VERSION "HSCAN6"

NS_ :

BS_:

BU_: BMS Tester TBOX VCU ISC SAC TC WLC

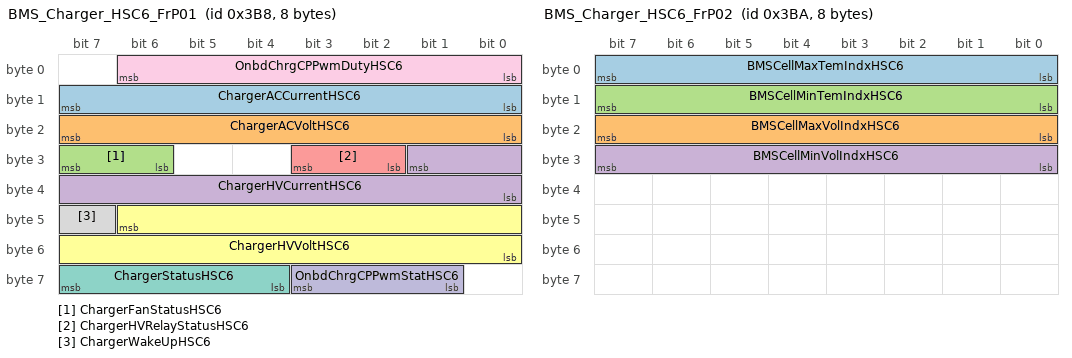
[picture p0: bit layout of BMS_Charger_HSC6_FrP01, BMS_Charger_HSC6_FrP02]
BO_ 952 BMS_Charger_HSC6_FrP01: 8 BMS
 SG_ ChargerACCurrentHSC6 : 15|8@0- (0.2,0) [0|50.8] "A"  Tester
 SG_ ChargerACVoltHSC6 : 23|8@0- (2,0) [0|508] "V"  Tester
 SG_ ChargerFanStatusHSC6 : 31|2@0+ (1,0) [0|3] ""  Tester
 SG_ ChargerHVCurrentHSC6 : 25|10@0- (0.05,0) [0|51.1] "A"  Tester,TBOX
 SG_ ChargerHVRelayStatusHSC6 : 27|2@0+ (1,0) [0|3] ""  Tester
 SG_ ChargerHVVoltHSC6 : 46|15@0- (0.02,0) [0|655.32] "V"  Tester,TBOX
 SG_ ChargerStatusHSC6 : 63|4@0+ (1,0) [0|15] ""  Tester,TBOX
 SG_ ChargerWakeUpHSC6 : 47|1@0+ (1,0) [0|1] ""  Tester
 SG_ OnbdChrgCPPwmDutyHSC6 : 6|7@0+ (1,0) [0|127] ""  Tester
 SG_ OnbdChrgCPPwmStatHSC6 : 59|3@0+ (1,0) [0|7] ""  TBOX

BO_ 954 BMS_Charger_HSC6_FrP02: 8 BMS
 SG_ BMSCellMaxTemIndxHSC6 : 7|8@0+ (1,0) [0|254] ""  TBOX
 SG_ BMSCellMaxVolIndxHSC6 : 23|8@0+ (1,0) [0|254] ""  TBOX
 SG_ BMSCellMinTemIndxHSC6 : 15|8@0+ (1,0) [0|254] ""  TBOX
 SG_ BMSCellMinVolIndxHSC6 : 31|8@0+ (1,0) [0|254] ""  TBOX

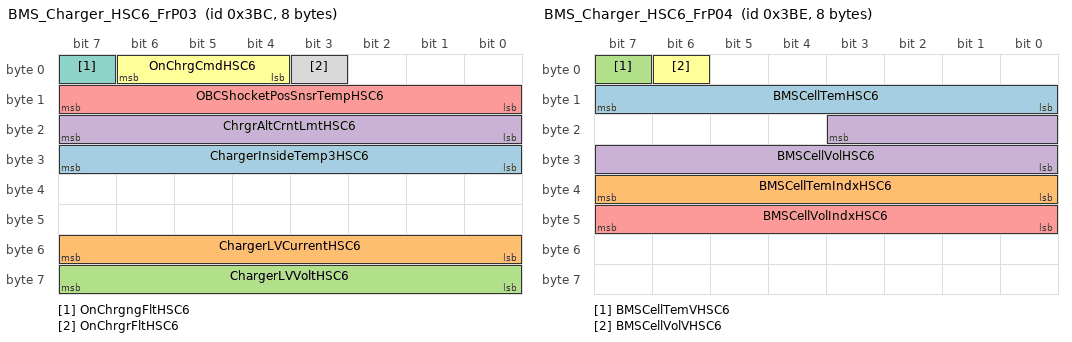
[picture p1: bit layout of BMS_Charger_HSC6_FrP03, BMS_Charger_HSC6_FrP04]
BO_ 956 BMS_Charger_HSC6_FrP03: 8 BMS
 SG_ ChargerInsideTemp3HSC6 : 31|8@0+ (1,-40) [-40|214] "DegC"  TBOX
 SG_ ChargerLVCurrentHSC6 : 55|8@0- (0.1,0) [0|25.4] "A"  Tester
 SG_ ChargerLVVoltHSC6 : 63|8@0- (0.1,0) [0|25.4] "V"  Tester
 SG_ ChrgrAltCrntLmtHSC6 : 23|8@0- (0.5,0) [0|127] "A"  Tester
 SG_ OBCShocketPosSnsrTempHSC6 : 15|8@0+ (1,-40) [-40|214] "¡æ"  TBOX
 SG_ OnChrgCmdHSC6 : 6|3@0+ (1,0) [0|7] ""  Tester
 SG_ OnChrgngFltHSC6 : 7|1@0+ (1,0) [0|1] ""  Tester
 SG_ OnChrgrFltHSC6 : 3|1@0+ (1,0) [0|1] ""  Tester

BO_ 958 BMS_Charger_HSC6_FrP04: 8 BMS
 SG_ BMSCellTemHSC6 : 15|8@0+ (1,-40) [-40|215] "E=N*1-40"  TBOX
 SG_ BMSCellTemIndxHSC6 : 39|8@0+ (1,0) [0|254] "E=N*1"  TBOX
 SG_ BMSCellTemVHSC6 : 7|1@0+ (1,0) [0|1] ""  TBOX
 SG_ BMSCellVolHSC6 : 19|12@0+ (0.001,1) [1|5.095] "E=N*0.001+1 V"  TBOX
 SG_ BMSCellVolIndxHSC6 : 47|8@0+ (1,0) [0|254] "E=N*1"  TBOX
 SG_ BMSCellVolVHSC6 : 6|1@0+ (1,0) [0|1] ""  TBOX

BO_ 659 BMS_HSC6_FrP00: 8 BMS
 SG_ BMSBalancingDoneHSC6 : 18|1@0+ (1,0) [0|1] ""  Tester
 SG_ BMSBalancingStatusHSC6 : 24|1@0+ (1,0) [0|1] ""  Tester,TBOX
 SG_ BMSCellBalancingCountHSC6 : 15|8@0+ (1,0) [0|253] ""  Tester
 SG_ BMSCellOverVoltHSC6 : 39|1@0+ (1,0) [0|1] ""  Tester
 SG_ BMSCellUnderVoltHSC6 : 19|1@0+ (1,0) [0|1] ""  Tester
 SG_ BMSContactorPowerCmdHSC6 : 16|1@0+ (1,0) [0|1] ""  Tester
 SG_ BMSContactorPowerMonHSC6 : 25|1@0+ (1,0) [0|1] ""  Tester
 SG_ BMSCrashCircuitStatusHSC6 : 17|1@0+ (1,0) [0|1] ""  Tester
 SG_ BMSEEpromWipHSC6 : 38|1@0+ (1,0) [0|1] ""  Tester
 SG_ BMSLVBatInputHSC6 : 7|8@0+ (0.1,0) [0|25.3] "V"  Tester,TBOX
 SG_ BMSModuleEnableHSC6 : 27|1@0+ (1,0) [0|1] ""  Tester
 SG_ BMSNegRelayStatusHSC6 : 47|2@0+ (1,0) [0|3] ""  Tester,TBOX
 SG_ BMSOffbdChargerWakeupHSC6 : 30|1@0+ (1,0) [0|1] ""  Tester
 SG_ BMSOnbdChargerWakeupHSC6 : 28|1@0+ (1,0) [0|1] ""  Tester
 SG_ BMSPosRelayStatusHSC6 : 33|2@0+ (1,0) [0|3] ""  Tester,TBOX
 SG_ BMSPreRelayStatusHSC6 : 35|2@0+ (1,0) [0|3] ""  Tester,TBOX
 SG_ BMSPTIsolationLevelHSC6 : 37|2@0+ (1,0) [0|3] ""  Tester
 SG_ BMSReadyHSC6 : 26|1@0+ (1,0) [0|1] ""  Tester
 SG_ BMSRelayStepHSC6 : 23|4@0+ (1,0) [0|15] ""  Tester,TBOX
 SG_ BMSVehicleWakeupHSC6 : 29|1@0+ (1,0) [0|1] ""  Tester,TBOX

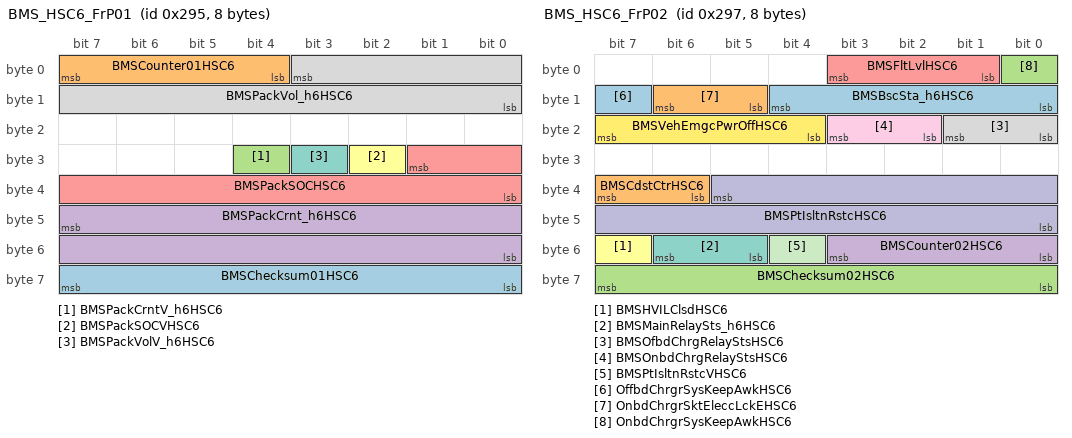
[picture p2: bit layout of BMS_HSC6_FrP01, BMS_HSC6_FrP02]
BO_ 661 BMS_HSC6_FrP01: 8 BMS
 SG_ BMSChecksum01HSC6 : 63|8@0+ (1,0) [0|255] ""  VCU
 SG_ BMSCounter01HSC6 : 7|4@0+ (1,0) [0|15] "count value"  VCU
 SG_ BMSPackCrntV_h6HSC6 : 28|1@0+ (1,0) [0|1] ""  Tester,TBOX,VCU,ISC,SAC,TC
 SG_ BMSPackCrnt_h6HSC6 : 47|16@0+ (0.05,-1000) [-1000|2276.75] "A"  Tester,TBOX,VCU,ISC,SAC,TC
 SG_ BMSPackSOCHSC6 : 25|10@0+ (0.1,0) [0|102.3] "%"  Tester,TBOX,VCU,ISC,SAC,TC
 SG_ BMSPackSOCVHSC6 : 26|1@0+ (1,0) [0|1] ""  Tester,TBOX,VCU,ISC,SAC,TC
 SG_ BMSPackVolV_h6HSC6 : 27|1@0+ (1,0) [0|1] ""  TBOX,VCU,ISC,SAC,TC
 SG_ BMSPackVol_h6HSC6 : 3|12@0+ (0.25,0) [0|1023.75] "V"  TBOX,VCU,ISC,SAC,TC

BO_ 663 BMS_HSC6_FrP02: 8 BMS
 SG_ BMSBscSta_h6HSC6 : 12|5@0+ (1,0) [0|31] ""  TBOX,VCU,ISC,SAC,TC
 SG_ BMSCdstCtrHSC6 : 39|2@0+ (1,0) [0|3] ""  TBOX,VCU
 SG_ BMSChecksum02HSC6 : 63|8@0+ (1,0) [0|255] ""  VCU
 SG_ BMSCounter02HSC6 : 51|4@0+ (1,0) [0|15] "count value"  VCU,ISC,SAC,TC
 SG_ BMSFltLvlHSC6 : 3|3@0+ (1,0) [0|7] ""  TBOX,VCU
 SG_ BMSHVILClsdHSC6 : 55|1@0+ (1,0) [0|1] ""  TBOX,VCU
 SG_ BMSMainRelaySts_h6HSC6 : 54|2@0+ (1,0) [0|3] ""  TBOX,VCU,ISC,SAC,TC
 SG_ BMSOfbdChrgRelayStsHSC6 : 17|2@0+ (1,0) [0|3] ""  Tester
 SG_ BMSOnbdChrgRelayStsHSC6 : 19|2@0+ (1,0) [0|3] ""  Tester
 SG_ BMSPtIsltnRstcHSC6 : 37|14@0+ (0.5,0) [0|8191.5] "kOhm"  TBOX,VCU
 SG_ BMSPtIsltnRstcVHSC6 : 52|1@0+ (1,0) [0|1] ""  TBOX,VCU
 SG_ BMSVehEmgcPwrOffHSC6 : 23|4@0+ (1,0) [0|15] ""  Tester
 SG_ OffbdChrgrSysKeepAwkHSC6 : 15|1@0+ (1,0) [0|1] ""  Tester,TBOX,VCU
 SG_ OnbdChrgrSktEleccLckEHSC6 : 14|2@0+ (1,0) [0|3] ""  VCU
 SG_ OnbdChrgrSysKeepAwkHSC6 : 0|1@0+ (1,0) [0|1] ""  Tester,TBOX,VCU

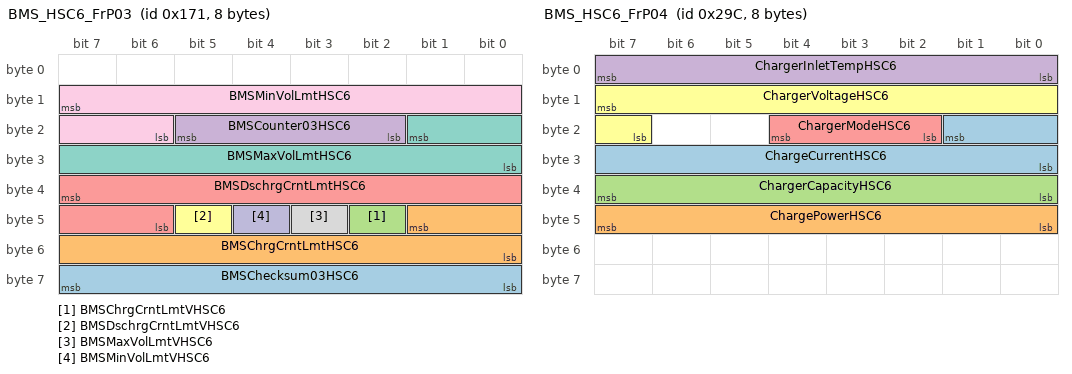
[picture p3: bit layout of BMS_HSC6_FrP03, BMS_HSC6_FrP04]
BO_ 369 BMS_HSC6_FrP03: 8 BMS
 SG_ BMSChecksum03HSC6 : 63|8@0+ (1,0) [0|255] ""  ISC,SAC,TC
 SG_ BMSChrgCrntLmtHSC6 : 41|10@0+ (1,-1023) [-1023|0] "A"  VCU,ISC,SAC,TC
 SG_ BMSChrgCrntLmtVHSC6 : 42|1@0+ (1,0) [0|1] ""  VCU,ISC,SAC,TC
 SG_ BMSCounter03HSC6 : 21|4@0+ (1,0) [0|15] "count value"  ISC,SAC,TC
 SG_ BMSDschrgCrntLmtHSC6 : 39|10@0+ (1,0) [0|1023] "A"  VCU,ISC,SAC,TC
 SG_ BMSDschrgCrntLmtVHSC6 : 45|1@0+ (1,0) [0|1] ""  VCU,ISC,SAC,TC
 SG_ BMSMaxVolLmtHSC6 : 17|10@0+ (1,0) [0|1023] "V"  ISC,SAC,TC
 SG_ BMSMaxVolLmtVHSC6 : 43|1@0+ (1,0) [0|1] ""  ISC,SAC,TC
 SG_ BMSMinVolLmtHSC6 : 15|10@0+ (1,0) [0|1023] "V"  ISC,SAC,TC
 SG_ BMSMinVolLmtVHSC6 : 44|1@0+ (1,0) [0|1] ""  ISC,SAC,TC

BO_ 668 BMS_HSC6_FrP04: 8 BMS
 SG_ ChargeCurrentHSC6 : 17|10@0+ (0.02,0) [0|20.44] "fail"  Tester
 SG_ ChargePowerHSC6 : 47|8@0+ (0.05,0) [0|12.7] "kw"  Tester
 SG_ ChargerCapacityHSC6 : 39|8@0- (1,0) [0|254] "Ah"  Tester
 SG_ ChargerInletTempHSC6 : 7|8@0+ (1,-40) [-40|214] "DegC"  Tester
 SG_ ChargerModeHSC6 : 20|3@0+ (1,0) [0|7] ""  Tester
 SG_ ChargerVoltageHSC6 : 15|9@0+ (1,0) [0|430] ""  Tester

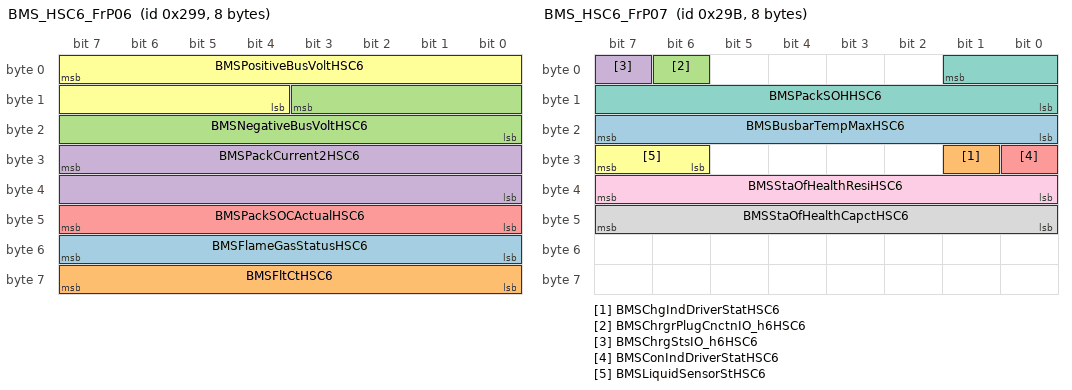
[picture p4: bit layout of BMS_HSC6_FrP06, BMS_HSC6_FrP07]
BO_ 665 BMS_HSC6_FrP06: 8 BMS
 SG_ BMSFlameGasStatusHSC6 : 55|8@0+ (1,0) [0|255] "%"  Tester
 SG_ BMSFltCtHSC6 : 63|8@0+ (1,0) [0|255] ""  Tester
 SG_ BMSNegativeBusVoltHSC6 : 11|12@0+ (0.25,-500) [-500|523.25] "V"  Tester
 SG_ BMSPackCurrent2HSC6 : 31|16@0+ (0.025,-1000) [-1000|638.325] "A"  Tester
 SG_ BMSPackSOCActualHSC6 : 47|8@0+ (0.5,0) [0|126.5] "%"  Tester
 SG_ BMSPositiveBusVoltHSC6 : 7|12@0+ (0.25,0) [0|1023.25] "V"  Tester

BO_ 667 BMS_HSC6_FrP07: 8 BMS
 SG_ BMSBusbarTempMaxHSC6 : 23|8@0+ (0.5,-40) [-40|86.5] "DegC"  Tester
 SG_ BMSChgIndDriverStatHSC6 : 25|1@0+ (1,0) [0|1] ""  Tester
 SG_ BMSChrgrPlugCnctnIO_h6HSC6 : 6|1@0+ (1,0) [0|1] ""  TBOX
 SG_ BMSChrgStsIO_h6HSC6 : 7|1@0+ (1,0) [0|1] ""  TBOX
 SG_ BMSConIndDriverStatHSC6 : 24|1@0+ (1,0) [0|1] ""  Tester
 SG_ BMSLiquidSensorStHSC6 : 31|2@0+ (1,0) [0|3] ""  Tester
 SG_ BMSPackSOHHSC6 : 1|10@0+ (0.1,0) [0|102.1] "%"  Tester,TBOX
 SG_ BMSStaOfHealthCapctHSC6 : 47|8@0+ (0.5,0) [0|126.5] "%"  Tester,TBOX
 SG_ BMSStaOfHealthResiHSC6 : 39|8@0+ (0.5,0) [0|126.5] "%"  Tester,TBOX

BO_ 1100 BMS_HSC6_FrP08: 1 BMS
 SG_ keep_network_BMSHSC6 : 0|1@0+ (1,0) [0|1] ""  TBOX
 SG_ keep_network_BMSHSC6_UB : 1|1@0+ (1,0) [0|1] ""  TBOX

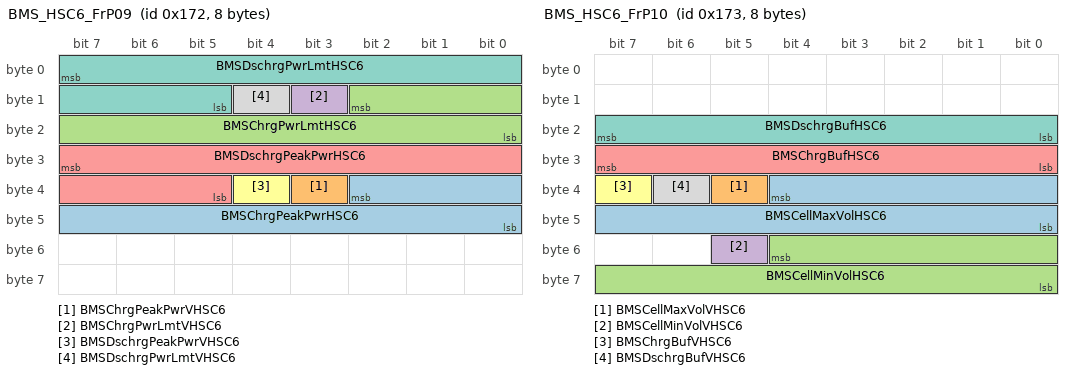
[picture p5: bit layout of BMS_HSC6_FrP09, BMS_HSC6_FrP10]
BO_ 370 BMS_HSC6_FrP09: 8 BMS
 SG_ BMSChrgPeakPwrHSC6 : 34|11@0+ (0.2,0) [0|409.4] "kw"  VCU
 SG_ BMSChrgPeakPwrVHSC6 : 35|1@0+ (1,0) [0|1] ""  VCU
 SG_ BMSChrgPwrLmtHSC6 : 10|11@0+ (0.2,0) [0|409.4] "kw"  VCU
 SG_ BMSChrgPwrLmtVHSC6 : 11|1@0+ (1,0) [0|1] ""  VCU
 SG_ BMSDschrgPeakPwrHSC6 : 31|11@0+ (0.2,0) [0|409.4] "kw"  VCU
 SG_ BMSDschrgPeakPwrVHSC6 : 36|1@0+ (1,0) [0|1] ""  VCU
 SG_ BMSDschrgPwrLmtHSC6 : 7|11@0+ (0.2,0) [0|409.4] "kw"  VCU
 SG_ BMSDschrgPwrLmtVHSC6 : 12|1@0+ (1,0) [0|1] ""  VCU

BO_ 371 BMS_HSC6_FrP10: 8 BMS
 SG_ BMSCellMaxVolHSC6 : 36|13@0+ (0.001,0) [0|8.191] "V"  Tester,TBOX
 SG_ BMSCellMaxVolVHSC6 : 37|1@0+ (1,0) [0|1] ""  Tester,TBOX
 SG_ BMSCellMinVolHSC6 : 52|13@0+ (0.001,0) [0|8.191] "V"  Tester,TBOX
 SG_ BMSCellMinVolVHSC6 : 53|1@0+ (1,0) [0|1] ""  Tester,TBOX
 SG_ BMSChrgBufHSC6 : 31|8@0+ (0.5,0) [0|127.5] "%"  VCU
 SG_ BMSChrgBufVHSC6 : 39|1@0+ (1,0) [0|1] ""  VCU
 SG_ BMSDschrgBufHSC6 : 23|8@0+ (0.5,0) [0|127.5] "%"  VCU
 SG_ BMSDschrgBufVHSC6 : 38|1@0+ (1,0) [0|1] ""  VCU

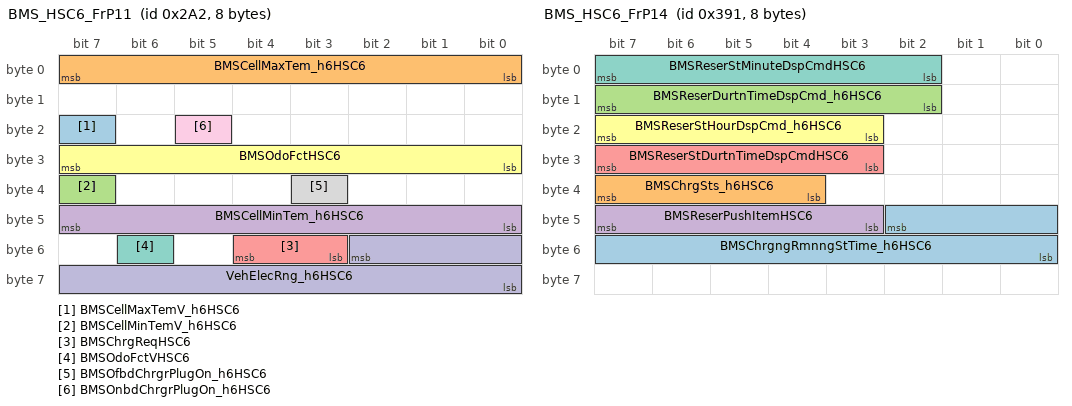
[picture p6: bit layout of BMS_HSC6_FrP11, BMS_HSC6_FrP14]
BO_ 674 BMS_HSC6_FrP11: 8 BMS
 SG_ BMSCellMaxTemV_h6HSC6 : 23|1@0+ (1,0) [0|1] ""  TBOX
 SG_ BMSCellMaxTem_h6HSC6 : 7|8@0+ (0.5,-40) [-40|87.5] "DegC"  TBOX
 SG_ BMSCellMinTemV_h6HSC6 : 39|1@0+ (1,0) [0|1] ""  TBOX
 SG_ BMSCellMinTem_h6HSC6 : 47|8@0+ (0.5,-40) [-40|87.5] "Deg C"  TBOX
 SG_ BMSChrgReqHSC6 : 52|2@0+ (1,0) [0|3] ""  VCU
 SG_ BMSOdoFctHSC6 : 31|8@0+ (0.5,0) [0|127.5] "%"  Tester
 SG_ BMSOdoFctVHSC6 : 54|1@0+ (1,0) [0|1] ""  Tester
 SG_ BMSOfbdChrgrPlugOn_h6HSC6 : 35|1@0+ (1,0) [0|1] ""  VCU
 SG_ BMSOnbdChrgrPlugOn_h6HSC6 : 21|1@0+ (1,0) [0|1] ""  TBOX
 SG_ VehElecRng_h6HSC6 : 50|11@0+ (1,0) [0|2047] "km"  TBOX

BO_ 939 BMS_HSC6_FrP12: 8 BMS
 SG_ HVBatElecEnrgAvgRate_h6HSC6 : 25|10@0+ (0.1,-20) [-20|82.3] "kwh/100km"  TBOX

BO_ 940 BMS_HSC6_FrP13: 8 BMS
 SG_ BMSPackSOCDspV_h6HSC6 : 37|1@0+ (1,0) [0|1] ""  TBOX
 SG_ BMSPackSOCDsp_h6HSC6 : 17|10@0+ (0.1,0) [0|102.3] "%"  TBOX

BO_ 913 BMS_HSC6_FrP14: 8 BMS
 SG_ BMSChrgngRmnngStTime_h6HSC6 : 42|11@0+ (1,0) [0|2047] "minute"  TBOX
 SG_ BMSChrgSts_h6HSC6 : 39|4@0+ (1,0) [0|15] ""  TBOX
 SG_ BMSReserDurtnTimeDspCmd_h6HSC6 : 15|6@0+ (0.5,0) [0|20] ""  TBOX
 SG_ BMSReserPushItemHSC6 : 47|5@0+ (1,0) [0|31] ""  TBOX
 SG_ BMSReserStDurtnTimeDspCmdHSC6 : 31|5@0+ (1,0) [0|23] ""  TBOX
 SG_ BMSReserStHourDspCmd_h6HSC6 : 23|5@0+ (1,0) [0|23] ""  TBOX
 SG_ BMSReserStMinuteDspCmdHSC6 : 7|6@0+ (1,0) [0|59] ""  TBOX

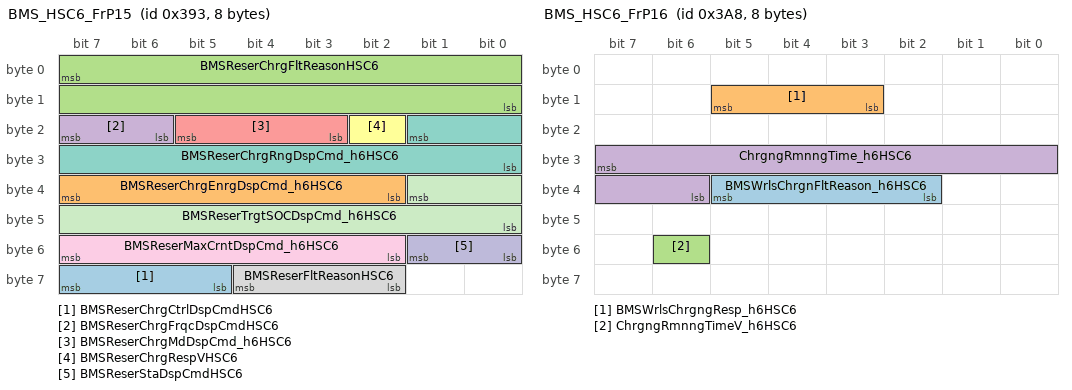
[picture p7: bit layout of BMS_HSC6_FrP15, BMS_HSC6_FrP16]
BO_ 915 BMS_HSC6_FrP15: 8 BMS
 SG_ BMSReserChrgCtrlDspCmdHSC6 : 63|3@0+ (1,0) [0|7] ""  TBOX
 SG_ BMSReserChrgEnrgDspCmd_h6HSC6 : 39|6@0+ (1,0) [0|63] ""  TBOX
 SG_ BMSReserChrgFltReasonHSC6 : 7|16@0+ (1,0) [0|65535] ""  TBOX
 SG_ BMSReserChrgFrqcDspCmdHSC6 : 23|2@0+ (1,0) [0|3] ""  TBOX
 SG_ BMSReserChrgMdDspCmd_h6HSC6 : 21|3@0+ (1,0) [0|7] ""  TBOX
 SG_ BMSReserChrgRespVHSC6 : 18|1@0+ (1,0) [0|1] ""  TBOX
 SG_ BMSReserChrgRngDspCmd_h6HSC6 : 17|10@0+ (1,0) [0|1023] ""  TBOX
 SG_ BMSReserFltReasonHSC6 : 60|3@0+ (1,0) [0|7] ""  TBOX
 SG_ BMSReserMaxCrntDspCmd_h6HSC6 : 55|6@0+ (1,0) [0|32] ""  TBOX
 SG_ BMSReserStaDspCmdHSC6 : 49|2@0+ (1,0) [0|3] ""  TBOX
 SG_ BMSReserTrgtSOCDspCmd_h6HSC6 : 33|10@0+ (0.1,0) [0|102.3] ""  TBOX

BO_ 936 BMS_HSC6_FrP16: 8 BMS
 SG_ BMSWrlsChrgnFltReason_h6HSC6 : 37|4@0+ (1,0) [0|15] ""  TBOX
 SG_ BMSWrlsChrgngResp_h6HSC6 : 13|3@0+ (1,0) [0|7] ""  TBOX
 SG_ ChrgngRmnngTimeV_h6HSC6 : 54|1@0+ (1,0) [0|1] ""  TBOX
 SG_ ChrgngRmnngTime_h6HSC6 : 31|10@0+ (1,0) [0|1023] "min"  TBOX

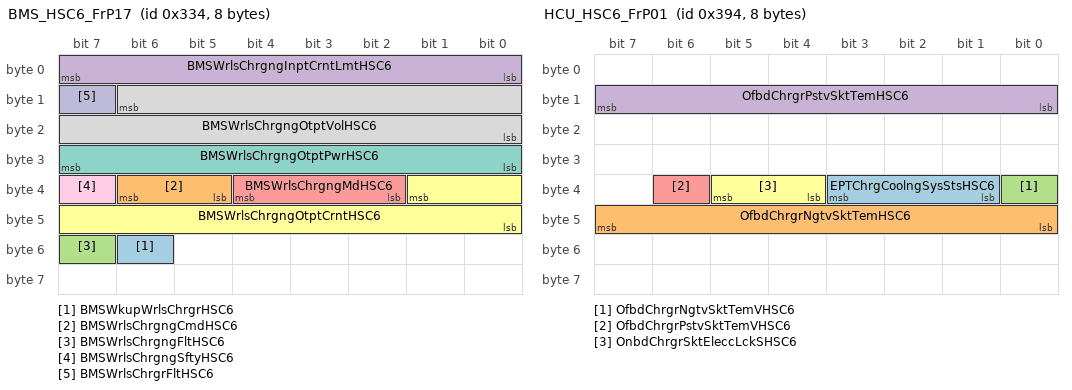
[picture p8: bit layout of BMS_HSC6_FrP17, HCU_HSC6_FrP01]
BO_ 820 BMS_HSC6_FrP17: 8 BMS
 SG_ BMSWkupWrlsChrgrHSC6 : 54|1@0+ (1,0) [0|1] ""  WLC
 SG_ BMSWrlsChrgngCmdHSC6 : 38|2@0+ (1,0) [0|3] ""  WLC
 SG_ BMSWrlsChrgngFltHSC6 : 55|1@0+ (1,0) [0|1] ""  WLC
 SG_ BMSWrlsChrgngInptCrntLmtHSC6 : 7|8@0+ (0.5,0) [0|127.5] "A"  WLC
 SG_ BMSWrlsChrgngMdHSC6 : 36|3@0+ (1,0) [0|7] ""  WLC
 SG_ BMSWrlsChrgngOtptCrntHSC6 : 33|10@0+ (0.05,0) [0|51.15] "A"  WLC
 SG_ BMSWrlsChrgngOtptPwrHSC6 : 31|8@0+ (0.05,0) [0|12.7] "kW"  WLC
 SG_ BMSWrlsChrgngOtptVolHSC6 : 14|15@0+ (0.02,0) [0|655.32] "V"  WLC
 SG_ BMSWrlsChrgngSftyHSC6 : 39|1@0+ (1,0) [0|1] ""  WLC
 SG_ BMSWrlsChrgrFltHSC6 : 15|1@0+ (1,0) [0|1] ""  WLC

BO_ 1091 BMS_HSC6_FrS00: 1 BMS
 SG_ wake_network_BMSHSC6 : 0|1@0+ (1,0) [0|1] ""  TBOX
 SG_ wake_network_BMSHSC6_UB : 1|1@0+ (1,0) [0|1] ""  TBOX

BO_ 916 HCU_HSC6_FrP01: 8 VCU
 SG_ EPTChrgCoolngSysStsHSC6 : 35|3@0+ (1,0) [0|7] ""  BMS
 SG_ OfbdChrgrNgtvSktTemHSC6 : 47|8@0+ (1,-40) [-40|215] "¡æ"  BMS
 SG_ OfbdChrgrNgtvSktTemVHSC6 : 32|1@0+ (1,0) [0|1] ""  BMS
 SG_ OfbdChrgrPstvSktTemHSC6 : 15|8@0+ (1,-40) [-40|215] "¡æ"  BMS
 SG_ OfbdChrgrPstvSktTemVHSC6 : 38|1@0+ (1,0) [0|1] ""  BMS
 SG_ OnbdChrgrSktEleccLckSHSC6 : 37|2@0+ (1,0) [0|3] ""  BMS

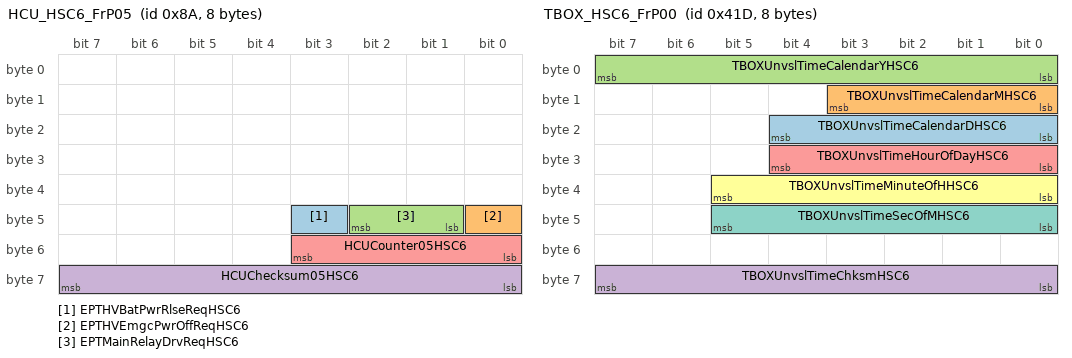
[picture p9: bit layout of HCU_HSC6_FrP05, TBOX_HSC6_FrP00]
BO_ 138 HCU_HSC6_FrP05: 8 VCU
 SG_ EPTHVBatPwrRlseReqHSC6 : 43|1@0+ (1,0) [0|1] ""  BMS
 SG_ EPTHVEmgcPwrOffReqHSC6 : 40|1@0+ (1,0) [0|1] ""  BMS
 SG_ EPTMainRelayDrvReqHSC6 : 42|2@0+ (1,0) [0|3] ""  BMS
 SG_ HCUChecksum05HSC6 : 63|8@0+ (1,0) [0|255] ""  BMS
 SG_ HCUCounter05HSC6 : 51|4@0+ (1,0) [0|15] ""  BMS

BO_ 150 ISC_HSC6_FrP04: 8 ISC
 SG_ ISGInvtrCrntHSC6 : 7|11@0+ (1,-1024) [-1024|1023] "A"  BMS
 SG_ ISGInvtrCrntVHSC6 : 12|1@0+ (1,0) [0|1] ""  BMS

BO_ 917 ISC_HSC6_FrP07: 8 ISC
 SG_ ISGInvtrVolHSC6 : 49|10@0+ (1,0) [0|1021] "V"  BMS
 SG_ ISGInvtrVolVHSC6 : 50|1@0+ (1,0) [0|1] ""  BMS

BO_ 1053 TBOX_HSC6_FrP00: 8 TBOX
 SG_ TBOXUnvslTimeCalendarDHSC6 : 20|5@0+ (1,0) [0|31] "day"  BMS
 SG_ TBOXUnvslTimeCalendarMHSC6 : 11|4@0+ (1,0) [0|15] ""  BMS
 SG_ TBOXUnvslTimeCalendarYHSC6 : 7|8@0+ (1,2000) [2000|2255] "year"  BMS
 SG_ TBOXUnvslTimeChksmHSC6 : 63|8@0+ (1,0) [0|255] ""  BMS
 SG_ TBOXUnvslTimeHourOfDayHSC6 : 28|5@0+ (1,0) [0|31] ""  BMS
 SG_ TBOXUnvslTimeMinuteOfHHSC6 : 37|6@0+ (1,0) [0|63] ""  BMS
 SG_ TBOXUnvslTimeSecOfMHSC6 : 45|6@0+ (1,0) [0|63] ""  BMS

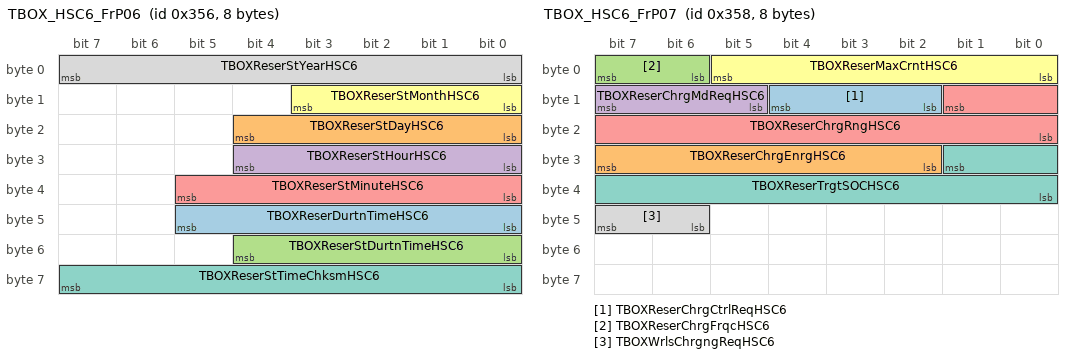
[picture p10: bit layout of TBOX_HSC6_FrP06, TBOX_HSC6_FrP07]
BO_ 854 TBOX_HSC6_FrP06: 8 TBOX
 SG_ TBOXReserDurtnTimeHSC6 : 45|6@0+ (0.5,0) [0|20] ""  BMS
 SG_ TBOXReserStDayHSC6 : 20|5@0+ (1,0) [0|31] ""  BMS
 SG_ TBOXReserStDurtnTimeHSC6 : 52|5@0+ (1,0) [0|23] ""  BMS
 SG_ TBOXReserStHourHSC6 : 28|5@0+ (1,0) [0|23] ""  BMS
 SG_ TBOXReserStMinuteHSC6 : 37|6@0+ (1,0) [0|59] ""  BMS
 SG_ TBOXReserStMonthHSC6 : 11|4@0+ (1,0) [0|15] ""  BMS
 SG_ TBOXReserStTimeChksmHSC6 : 63|8@0+ (1,0) [0|255] ""  BMS
 SG_ TBOXReserStYearHSC6 : 7|8@0+ (1,2000) [2000|2255] ""  BMS

BO_ 856 TBOX_HSC6_FrP07: 8 TBOX
 SG_ TBOXReserChrgCtrlReqHSC6 : 12|3@0+ (1,0) [0|7] ""  BMS
 SG_ TBOXReserChrgEnrgHSC6 : 31|6@0+ (1,0) [0|63] ""  BMS
 SG_ TBOXReserChrgFrqcHSC6 : 7|2@0+ (1,0) [0|3] ""  BMS
 SG_ TBOXReserChrgMdReqHSC6 : 15|3@0+ (1,0) [0|7] ""  BMS
 SG_ TBOXReserChrgRngHSC6 : 9|10@0+ (1,0) [0|1023] ""  BMS
 SG_ TBOXReserMaxCrntHSC6 : 5|6@0+ (1,0) [0|32] ""  BMS
 SG_ TBOXReserTrgtSOCHSC6 : 25|10@0+ (0.1,0) [0|102.3] ""  BMS
 SG_ TBOXWrlsChrgngReqHSC6 : 47|2@0+ (1,0) [0|3] ""  BMS

BO_ 1055 TBOX_HSC6_NWM: 3 TBOX
 SG_ network_mode_h6 : 7|8@0+ (1,0) [0|255] ""  BMS
 SG_ signal_config_id_h6 : 15|16@0+ (1,0) [0|65535] ""  BMS

BO_ 153 TC_HSC6_FrP02: 8 TC
 SG_ TMInvtrCrntHSC6 : 23|11@0+ (1,-1024) [-1024|1023] "A"  BMS
 SG_ TMInvtrCrntVHSC6 : 28|1@0+ (1,0) [0|1] ""  BMS

BO_ 331 TC_HSC6_FrP08: 8 TC
 SG_ TMInvtrVolHSC6 : 1|10@0+ (1,0) [0|1023] "V"  BMS
 SG_ TMInvtrVolVHSC6 : 2|1@0+ (1,0) [0|1] ""  BMS

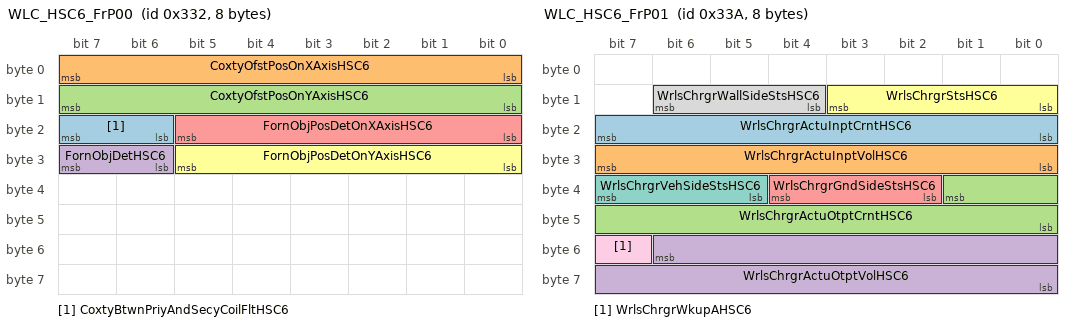
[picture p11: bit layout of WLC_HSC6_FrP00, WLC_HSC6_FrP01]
BO_ 818 WLC_HSC6_FrP00: 8 WLC
 SG_ CoxtyBtwnPriyAndSecyCoilFltHSC6 : 23|2@0+ (1,0) [0|3] ""  BMS
 SG_ CoxtyOfstPosOnXAxisHSC6 : 7|8@0+ (1,-127) [-127|127] ""  BMS
 SG_ CoxtyOfstPosOnYAxisHSC6 : 15|8@0+ (1,-127) [-127|127] ""  BMS
 SG_ FornObjDetHSC6 : 31|2@0+ (1,0) [0|3] ""  BMS
 SG_ FornObjPosDetOnXAxisHSC6 : 21|6@0+ (1,0) [0|63] ""  BMS
 SG_ FornObjPosDetOnYAxisHSC6 : 29|6@0+ (1,0) [0|63] ""  BMS

BO_ 826 WLC_HSC6_FrP01: 8 WLC
 SG_ WrlsChrgrActuInptCrntHSC6 : 23|8@0+ (0.2,0) [0|51] "A"  BMS
 SG_ WrlsChrgrActuInptVolHSC6 : 31|8@0+ (2,0) [0|508] "V"  BMS
 SG_ WrlsChrgrActuOtptCrntHSC6 : 33|10@0+ (0.05,0) [0|51.15] "A"  BMS
 SG_ WrlsChrgrActuOtptVolHSC6 : 54|15@0+ (0.02,0) [0|655.32] "V"  BMS
 SG_ WrlsChrgrGndSideStsHSC6 : 36|3@0+ (1,0) [0|7] ""  BMS
 SG_ WrlsChrgrStsHSC6 : 11|4@0+ (1,0) [0|15] ""  BMS
 SG_ WrlsChrgrVehSideStsHSC6 : 39|3@0+ (1,0) [0|7] ""  BMS
 SG_ WrlsChrgrWallSideStsHSC6 : 14|3@0+ (1,0) [0|7] ""  BMS
 SG_ WrlsChrgrWkupAHSC6 : 55|1@0+ (1,0) [0|1] ""  BMS

CM_ SG_ 663 OffbdChrgrSysKeepAwkHSC6 "Offboard Charger System Keep Awake";
CM_ SG_ 668 ChargeCurrentHSC6 "charging current setpoint";
CM_ SG_ 668 ChargePowerHSC6 "charging power setpoint";
CM_ SG_ 667 BMSChrgrPlugCnctnIO_h6HSC6 "Battery Management System Charger Plug Connection Indication On
";
CM_ SG_ 667 BMSChrgStsIO_h6HSC6 "
";
CM_ SG_ 940 BMSPackSOCDspV_h6HSC6 "Battery Management System Pack State Of Charge Display Validity";
CM_ SG_ 1055 network_mode_h6 "NM signal: this signal contains the intended mode of the network. This signal controls the frame mode used by the slave nodes";
CM_ SG_ 1055 signal_config_id_h6 "NM signal: this is the identification number of the signal configuration used. Read by the slave nodes to determine if they have the correct configuration or not";
BA_DEF_  "BaudRate" FLOAT 1000 1000000;
BA_DEF_ SG_  "GenSigLongName" STRING ;
BA_DEF_ BO_  "GenMsgSendType" ENUM  "cyclic","spontaneous","cyclicIfActive","spontaneousWithDelay","OnChangeWithRepetition","Immediate";
BA_DEF_ BO_  "GenMsgCycleTime" FLOAT 0 300000;
BA_DEF_ SG_  "GenSigStartValue" INT -9.22337203685478E+018 1.84467440737096E+019;
BA_DEF_DEF_  "BaudRate" 1000;
BA_DEF_DEF_  "GenSigLongName" "";
BA_DEF_DEF_  "GenMsgSendType" "";
BA_DEF_DEF_  "GenMsgCycleTime" 0;
BA_DEF_DEF_  "GenSigStartValue" 0;
BA_ "BaudRate" 500000;
BA_ "GenMsgSendType" BO_ 952 0;
BA_ "GenMsgCycleTime" BO_ 952 100;
BA_ "GenMsgSendType" BO_ 954 0;
BA_ "GenMsgCycleTime" BO_ 954 100;
BA_ "GenMsgSendType" BO_ 956 0;
BA_ "GenMsgCycleTime" BO_ 956 100;
BA_ "GenMsgSendType" BO_ 958 0;
BA_ "GenMsgCycleTime" BO_ 958 200;
BA_ "GenMsgSendType" BO_ 659 0;
BA_ "GenMsgCycleTime" BO_ 659 50;
BA_ "GenMsgSendType" BO_ 661 0;
BA_ "GenMsgCycleTime" BO_ 661 20;
BA_ "GenMsgSendType" BO_ 663 0;
BA_ "GenMsgCycleTime" BO_ 663 50;
BA_ "GenMsgSendType" BO_ 369 0;
BA_ "GenMsgCycleTime" BO_ 369 20;
BA_ "GenMsgSendType" BO_ 668 0;
BA_ "GenMsgCycleTime" BO_ 668 100;
BA_ "GenMsgSendType" BO_ 665 0;
BA_ "GenMsgCycleTime" BO_ 665 50;
BA_ "GenMsgSendType" BO_ 667 0;
BA_ "GenMsgCycleTime" BO_ 667 50;
BA_ "GenMsgSendType" BO_ 1100 0;
BA_ "GenMsgCycleTime" BO_ 1100 100;
BA_ "GenMsgSendType" BO_ 370 0;
BA_ "GenMsgCycleTime" BO_ 370 20;
BA_ "GenMsgSendType" BO_ 371 0;
BA_ "GenMsgCycleTime" BO_ 371 20;
BA_ "GenMsgSendType" BO_ 674 0;
BA_ "GenMsgCycleTime" BO_ 674 100;
BA_ "GenMsgSendType" BO_ 939 0;
BA_ "GenMsgCycleTime" BO_ 939 100;
BA_ "GenMsgSendType" BO_ 940 0;
BA_ "GenMsgCycleTime" BO_ 940 100;
BA_ "GenMsgSendType" BO_ 913 0;
BA_ "GenMsgCycleTime" BO_ 913 100;
BA_ "GenMsgSendType" BO_ 915 0;
BA_ "GenMsgCycleTime" BO_ 915 100;
BA_ "GenMsgSendType" BO_ 936 0;
BA_ "GenMsgCycleTime" BO_ 936 100;
BA_ "GenMsgSendType" BO_ 820 0;
BA_ "GenMsgCycleTime" BO_ 820 100;
BA_ "GenMsgSendType" BO_ 1091 1;
BA_ "GenMsgSendType" BO_ 916 0;
BA_ "GenMsgCycleTime" BO_ 916 100;
BA_ "GenMsgSendType" BO_ 138 0;
BA_ "GenMsgCycleTime" BO_ 138 10;
BA_ "GenMsgSendType" BO_ 150 0;
BA_ "GenMsgCycleTime" BO_ 150 10;
BA_ "GenMsgSendType" BO_ 917 0;
BA_ "GenMsgCycleTime" BO_ 917 100;
BA_ "GenMsgSendType" BO_ 1053 0;
BA_ "GenMsgCycleTime" BO_ 1053 200;
BA_ "GenMsgSendType" BO_ 854 0;
BA_ "GenMsgCycleTime" BO_ 854 100;
BA_ "GenMsgSendType" BO_ 856 0;
BA_ "GenMsgCycleTime" BO_ 856 100;
BA_ "GenMsgSendType" BO_ 1055 5;
BA_ "GenMsgSendType" BO_ 153 0;
BA_ "GenMsgCycleTime" BO_ 153 10;
BA_ "GenMsgSendType" BO_ 331 0;
BA_ "GenMsgCycleTime" BO_ 331 10;
BA_ "GenMsgSendType" BO_ 818 0;
BA_ "GenMsgCycleTime" BO_ 818 100;
BA_ "GenMsgSendType" BO_ 826 0;
BA_ "GenMsgCycleTime" BO_ 826 100;
BA_ "GenSigLongName" SG_ 952 ChargerACCurrentHSC6 "Charger Ac Current";
BA_ "GenSigLongName" SG_ 952 ChargerACVoltHSC6 "Charger Ac Voltage";
BA_ "GenSigLongName" SG_ 952 ChargerFanStatusHSC6 "Charger Fan Status";
BA_ "GenSigLongName" SG_ 952 ChargerHVCurrentHSC6 "Charger Hv Current";
BA_ "GenSigLongName" SG_ 952 ChargerHVRelayStatusHSC6 "Charger Hv Relay Status";
BA_ "GenSigLongName" SG_ 952 ChargerHVVoltHSC6 "Charger Hv Voltage";
BA_ "GenSigLongName" SG_ 952 ChargerStatusHSC6 "Charger Status";
BA_ "GenSigLongName" SG_ 952 ChargerWakeUpHSC6 "Charger Wakeup";
BA_ "GenSigStartValue" SG_ 954 BMSCellMaxTemIndxHSC6 255;
BA_ "GenSigStartValue" SG_ 954 BMSCellMaxVolIndxHSC6 255;
BA_ "GenSigStartValue" SG_ 954 BMSCellMinTemIndxHSC6 255;
BA_ "GenSigStartValue" SG_ 954 BMSCellMinVolIndxHSC6 255;
BA_ "GenSigLongName" SG_ 956 ChargerLVCurrentHSC6 "Charger Lv Current";
BA_ "GenSigLongName" SG_ 956 ChargerLVVoltHSC6 "Charger Lv Voltage";
BA_ "GenSigLongName" SG_ 956 ChrgrAltCrntLmtHSC6 "Charger Alternative Current Limit";
BA_ "GenSigLongName" SG_ 956 OnChrgngFltHSC6 "Onboard Charging Fault";
BA_ "GenSigLongName" SG_ 956 OnChrgrFltHSC6 "Onboard Charger Fault";
BA_ "GenSigStartValue" SG_ 958 BMSCellTemHSC6 255;
BA_ "GenSigStartValue" SG_ 958 BMSCellTemIndxHSC6 255;
BA_ "GenSigStartValue" SG_ 958 BMSCellTemVHSC6 1;
BA_ "GenSigStartValue" SG_ 958 BMSCellVolHSC6 4095;
BA_ "GenSigStartValue" SG_ 958 BMSCellVolIndxHSC6 255;
BA_ "GenSigStartValue" SG_ 958 BMSCellVolVHSC6 1;
BA_ "GenSigLongName" SG_ 659 BMSBalancingDoneHSC6 "Battery Management System Balancing Done";
BA_ "GenSigLongName" SG_ 659 BMSBalancingStatusHSC6 "Battery Management System Balancing Status";
BA_ "GenSigStartValue" SG_ 659 BMSCellBalancingCountHSC6 255;
BA_ "GenSigLongName" SG_ 659 BMSCellBalancingCountHSC6 "Battery Management System Cell Balancing Count";
BA_ "GenSigLongName" SG_ 659 BMSCellOverVoltHSC6 "Battery Management System Cell Over Voltage";
BA_ "GenSigLongName" SG_ 659 BMSCellUnderVoltHSC6 "Battery Management System Cell Under Voltage";
BA_ "GenSigLongName" SG_ 659 BMSContactorPowerCmdHSC6 "Battery Management System Contactor Power Relay Command State";
BA_ "GenSigLongName" SG_ 659 BMSContactorPowerMonHSC6 "Battery Management System Contactor Power Relay Monitor";
BA_ "GenSigLongName" SG_ 659 BMSCrashCircuitStatusHSC6 "Battery Management System Crash Circuit Status";
BA_ "GenSigLongName" SG_ 659 BMSEEpromWipHSC6 "Battery Management System Eeprom Write In Progress";
BA_ "GenSigStartValue" SG_ 659 BMSLVBatInputHSC6 255;
BA_ "GenSigLongName" SG_ 659 BMSLVBatInputHSC6 "Battery Management System Low Voltage Battery Input";
BA_ "GenSigLongName" SG_ 659 BMSModuleEnableHSC6 "Battery Management System Module Enable";
BA_ "GenSigLongName" SG_ 659 BMSNegRelayStatusHSC6 "Battery Management System Negative Relay Status";
BA_ "GenSigLongName" SG_ 659 BMSOffbdChargerWakeupHSC6 "Battery Management System Offboard Charger Wakeup";
BA_ "GenSigLongName" SG_ 659 BMSOnbdChargerWakeupHSC6 "Battery Management System Onboard Charger Wakeup";
BA_ "GenSigLongName" SG_ 659 BMSPosRelayStatusHSC6 "Battery Management System Positive Relay Status";
BA_ "GenSigLongName" SG_ 659 BMSPreRelayStatusHSC6 "Battery Management System Precharge Relay Status";
BA_ "GenSigLongName" SG_ 659 BMSPTIsolationLevelHSC6 "Battery Management System Powertrain Isolation Level";
BA_ "GenSigLongName" SG_ 659 BMSReadyHSC6 "Battery Management System Ready";
BA_ "GenSigLongName" SG_ 659 BMSRelayStepHSC6 "Battery Management System Relay Step";
BA_ "GenSigLongName" SG_ 659 BMSVehicleWakeupHSC6 "Battery Management System Vehicle Wakeup";
BA_ "GenSigLongName" SG_ 661 BMSChecksum01HSC6 "Battery Management System Frame01 Checksum";
BA_ "GenSigLongName" SG_ 661 BMSCounter01HSC6 "Battery Management System Frame01 Rolling Counter";
BA_ "GenSigStartValue" SG_ 661 BMSPackCrntV_h6HSC6 1;
BA_ "GenSigLongName" SG_ 661 BMSPackCrntV_h6HSC6 "Battery Management System Pack Current Validity";
BA_ "GenSigStartValue" SG_ 661 BMSPackCrnt_h6HSC6 65535;
BA_ "GenSigLongName" SG_ 661 BMSPackCrnt_h6HSC6 "Battery Management System Pack Current";
BA_ "GenSigStartValue" SG_ 661 BMSPackSOCHSC6 1023;
BA_ "GenSigLongName" SG_ 661 BMSPackSOCHSC6 "Battery Management System Pack State Of Charge";
BA_ "GenSigStartValue" SG_ 661 BMSPackSOCVHSC6 1;
BA_ "GenSigLongName" SG_ 661 BMSPackSOCVHSC6 "Battery Management System Pack State Of Charge Validity";
BA_ "GenSigStartValue" SG_ 661 BMSPackVolV_h6HSC6 1;
BA_ "GenSigLongName" SG_ 661 BMSPackVolV_h6HSC6 "Battery Management System Pack Voltage Validity";
BA_ "GenSigStartValue" SG_ 661 BMSPackVol_h6HSC6 4095;
BA_ "GenSigLongName" SG_ 661 BMSPackVol_h6HSC6 "Battery Management System Pack Voltage";
BA_ "GenSigLongName" SG_ 663 BMSBscSta_h6HSC6 "Battery Management System Basic State";
BA_ "GenSigLongName" SG_ 663 BMSCdstCtrHSC6 "Battery Management System Coldstart Counter";
BA_ "GenSigLongName" SG_ 663 BMSChecksum02HSC6 "Battery Management System Frame02 Checksum";
BA_ "GenSigLongName" SG_ 663 BMSCounter02HSC6 "Battery Management System Counter Frp02";
BA_ "GenSigLongName" SG_ 663 BMSFltLvlHSC6 "Battery Management System Fault Level";
BA_ "GenSigStartValue" SG_ 663 BMSHVILClsdHSC6 1;
BA_ "GenSigLongName" SG_ 663 BMSHVILClsdHSC6 "Battery Management System High Voltage Interlock Loop Closed";
BA_ "GenSigLongName" SG_ 663 BMSMainRelaySts_h6HSC6 "Battery Management System Main Relay Status";
BA_ "GenSigLongName" SG_ 663 BMSOfbdChrgRelayStsHSC6 "Battery Management System Offboard Charge Relay Status";
BA_ "GenSigLongName" SG_ 663 BMSOnbdChrgRelayStsHSC6 "Battery Management System Onboard Charge Relay Status";
BA_ "GenSigStartValue" SG_ 663 BMSPtIsltnRstcHSC6 16383;
BA_ "GenSigLongName" SG_ 663 BMSPtIsltnRstcHSC6 "Battery Management System Powertrain Isolation Resistance";
BA_ "GenSigStartValue" SG_ 663 BMSPtIsltnRstcVHSC6 1;
BA_ "GenSigLongName" SG_ 663 BMSPtIsltnRstcVHSC6 "Battery Management System Powertrain Isolation Resistance Validity";
BA_ "GenSigStartValue" SG_ 663 BMSVehEmgcPwrOffHSC6 14;
BA_ "GenSigLongName" SG_ 663 BMSVehEmgcPwrOffHSC6 "Battery Management System Vehicle Emergency Power Off";
BA_ "GenSigLongName" SG_ 663 OnbdChrgrSktEleccLckEHSC6 "Onboard Charger Socket Electronic Lock Enabled";
BA_ "GenSigLongName" SG_ 663 OnbdChrgrSysKeepAwkHSC6 "Onboard Charger System Keep Awake";
BA_ "GenSigLongName" SG_ 369 BMSChecksum03HSC6 "Battery Management System Checksum Frp03";
BA_ "GenSigLongName" SG_ 369 BMSChrgCrntLmtHSC6 "Battery Management System Charge Current Limit";
BA_ "GenSigStartValue" SG_ 369 BMSChrgCrntLmtVHSC6 1;
BA_ "GenSigLongName" SG_ 369 BMSChrgCrntLmtVHSC6 "Battery Management System Charge Current Limit Validity";
BA_ "GenSigLongName" SG_ 369 BMSCounter03HSC6 "Battery Management System Counter Frp03";
BA_ "GenSigStartValue" SG_ 369 BMSDschrgCrntLmtHSC6 1023;
BA_ "GenSigLongName" SG_ 369 BMSDschrgCrntLmtHSC6 "Battery Management System Discharge Current Limit";
BA_ "GenSigStartValue" SG_ 369 BMSDschrgCrntLmtVHSC6 1;
BA_ "GenSigLongName" SG_ 369 BMSDschrgCrntLmtVHSC6 "Battery Management System Discharge Current Limit Validity";
BA_ "GenSigStartValue" SG_ 369 BMSMaxVolLmtHSC6 1023;
BA_ "GenSigLongName" SG_ 369 BMSMaxVolLmtHSC6 "Battery Management System Maximum Voltage Limit";
BA_ "GenSigStartValue" SG_ 369 BMSMaxVolLmtVHSC6 1;
BA_ "GenSigLongName" SG_ 369 BMSMaxVolLmtVHSC6 "Battery Management System Maximum Voltage Limit Validity";
BA_ "GenSigStartValue" SG_ 369 BMSMinVolLmtHSC6 1023;
BA_ "GenSigLongName" SG_ 369 BMSMinVolLmtHSC6 "Battery Management System Minimum Voltage Limit";
BA_ "GenSigStartValue" SG_ 369 BMSMinVolLmtVHSC6 1;
BA_ "GenSigLongName" SG_ 369 BMSMinVolLmtVHSC6 "Battery Management System Minimum Voltage Limit Validity";
BA_ "GenSigLongName" SG_ 668 ChargerCapacityHSC6 "Charger Capacity";
BA_ "GenSigLongName" SG_ 668 ChargerModeHSC6 "Charger Mode";
BA_ "GenSigStartValue" SG_ 668 ChargerVoltageHSC6 511;
BA_ "GenSigStartValue" SG_ 665 BMSFlameGasStatusHSC6 255;
BA_ "GenSigLongName" SG_ 665 BMSFlameGasStatusHSC6 "Battery Management System Flammable Gas Detector Duty Cycle";
BA_ "GenSigStartValue" SG_ 665 BMSFltCtHSC6 255;
BA_ "GenSigLongName" SG_ 665 BMSFltCtHSC6 "Battery Management System Fault Count";
BA_ "GenSigStartValue" SG_ 665 BMSNegativeBusVoltHSC6 4095;
BA_ "GenSigLongName" SG_ 665 BMSNegativeBusVoltHSC6 "Battery Management System Negative Bus Voltage";
BA_ "GenSigStartValue" SG_ 665 BMSPackCurrent2HSC6 65535;
BA_ "GenSigLongName" SG_ 665 BMSPackCurrent2HSC6 "Battery Management System Pack Current 2";
BA_ "GenSigStartValue" SG_ 665 BMSPackSOCActualHSC6 254;
BA_ "GenSigLongName" SG_ 665 BMSPackSOCActualHSC6 "Battery Management System Pack Actual State Of Charge";
BA_ "GenSigStartValue" SG_ 665 BMSPositiveBusVoltHSC6 4095;
BA_ "GenSigLongName" SG_ 665 BMSPositiveBusVoltHSC6 "Battery Management System Positive Bus Voltage";
BA_ "GenSigStartValue" SG_ 667 BMSBusbarTempMaxHSC6 255;
BA_ "GenSigLongName" SG_ 667 BMSChgIndDriverStatHSC6 "Battery Management System Charging Indication Driver Status";
BA_ "GenSigStartValue" SG_ 667 BMSChrgrPlugCnctnIO_h6HSC6 1;
BA_ "GenSigStartValue" SG_ 667 BMSChrgStsIO_h6HSC6 1;
BA_ "GenSigLongName" SG_ 667 BMSChrgStsIO_h6HSC6 "Battery Management System Charge Status Indication On";
BA_ "GenSigStartValue" SG_ 667 BMSConIndDriverStatHSC6 1;
BA_ "GenSigLongName" SG_ 667 BMSConIndDriverStatHSC6 "Battery Management System Connection Indication Driver Status";
BA_ "GenSigLongName" SG_ 667 BMSLiquidSensorStHSC6 "Battery Management System Liquid Level Seneor Status";
BA_ "GenSigStartValue" SG_ 667 BMSPackSOHHSC6 1022;
BA_ "GenSigLongName" SG_ 667 BMSPackSOHHSC6 "Battery Management System Pack State Of Health";
BA_ "GenSigStartValue" SG_ 667 BMSStaOfHealthCapctHSC6 255;
BA_ "GenSigLongName" SG_ 667 BMSStaOfHealthCapctHSC6 "Battery Management System State Of Health Capacity";
BA_ "GenSigStartValue" SG_ 667 BMSStaOfHealthResiHSC6 255;
BA_ "GenSigLongName" SG_ 667 BMSStaOfHealthResiHSC6 "Battery Management System State Of Health Resistance";
BA_ "GenSigLongName" SG_ 1100 keep_network_BMSHSC6 "Keep Network Battery Management System";
BA_ "GenSigStartValue" SG_ 370 BMSChrgPeakPwrHSC6 2047;
BA_ "GenSigLongName" SG_ 370 BMSChrgPeakPwrHSC6 "Battery Management System Charge Peak Power";
BA_ "GenSigStartValue" SG_ 370 BMSChrgPeakPwrVHSC6 1;
BA_ "GenSigLongName" SG_ 370 BMSChrgPeakPwrVHSC6 "Battery Management System Charge Peak Power Validity";
BA_ "GenSigStartValue" SG_ 370 BMSChrgPwrLmtHSC6 2047;
BA_ "GenSigLongName" SG_ 370 BMSChrgPwrLmtHSC6 "Battery Management System Charge Power Limit";
BA_ "GenSigStartValue" SG_ 370 BMSChrgPwrLmtVHSC6 1;
BA_ "GenSigLongName" SG_ 370 BMSChrgPwrLmtVHSC6 "Battery Management System Charge Power Limit Validity";
BA_ "GenSigStartValue" SG_ 370 BMSDschrgPeakPwrHSC6 2047;
BA_ "GenSigLongName" SG_ 370 BMSDschrgPeakPwrHSC6 "Battery Management System Discharge Peak Power";
BA_ "GenSigStartValue" SG_ 370 BMSDschrgPeakPwrVHSC6 1;
BA_ "GenSigLongName" SG_ 370 BMSDschrgPeakPwrVHSC6 "Battery Management System Discharge Peak Power Validity";
BA_ "GenSigStartValue" SG_ 370 BMSDschrgPwrLmtHSC6 2047;
BA_ "GenSigLongName" SG_ 370 BMSDschrgPwrLmtHSC6 "Battery Management System Discharge Power Limit";
BA_ "GenSigStartValue" SG_ 370 BMSDschrgPwrLmtVHSC6 1;
BA_ "GenSigLongName" SG_ 370 BMSDschrgPwrLmtVHSC6 "Battery Management System Discharge Power Limit Validity";
BA_ "GenSigStartValue" SG_ 371 BMSCellMaxVolHSC6 8191;
BA_ "GenSigLongName" SG_ 371 BMSCellMaxVolHSC6 "Battery Management System Cell Maximum Voltage";
BA_ "GenSigStartValue" SG_ 371 BMSCellMaxVolVHSC6 1;
BA_ "GenSigLongName" SG_ 371 BMSCellMaxVolVHSC6 "Battery Management System Cell Maximum Voltage Validity";
BA_ "GenSigStartValue" SG_ 371 BMSCellMinVolHSC6 8191;
BA_ "GenSigLongName" SG_ 371 BMSCellMinVolHSC6 "Battery Management System Cell Minimum Voltage";
BA_ "GenSigStartValue" SG_ 371 BMSCellMinVolVHSC6 1;
BA_ "GenSigLongName" SG_ 371 BMSCellMinVolVHSC6 "Battery Management System Cell Minimum Voltage Validity";
BA_ "GenSigStartValue" SG_ 371 BMSChrgBufHSC6 255;
BA_ "GenSigLongName" SG_ 371 BMSChrgBufHSC6 "Battery Management System Charge Buffer";
BA_ "GenSigStartValue" SG_ 371 BMSChrgBufVHSC6 1;
BA_ "GenSigLongName" SG_ 371 BMSChrgBufVHSC6 "Battery Management System Charge Buffer Validity";
BA_ "GenSigStartValue" SG_ 371 BMSDschrgBufHSC6 255;
BA_ "GenSigLongName" SG_ 371 BMSDschrgBufHSC6 "Battery Management System Discharge Buffer";
BA_ "GenSigStartValue" SG_ 371 BMSDschrgBufVHSC6 1;
BA_ "GenSigLongName" SG_ 371 BMSDschrgBufVHSC6 "Battery Management System Discharge Buffer Validity";
BA_ "GenSigStartValue" SG_ 674 BMSCellMaxTemV_h6HSC6 1;
BA_ "GenSigLongName" SG_ 674 BMSCellMaxTemV_h6HSC6 "Battery Management System Cell Maximum Temperature Validity";
BA_ "GenSigStartValue" SG_ 674 BMSCellMaxTem_h6HSC6 255;
BA_ "GenSigLongName" SG_ 674 BMSCellMaxTem_h6HSC6 "Battery Management System Cell Maximum Temperature";
BA_ "GenSigStartValue" SG_ 674 BMSCellMinTemV_h6HSC6 1;
BA_ "GenSigLongName" SG_ 674 BMSCellMinTemV_h6HSC6 "Battery Management System Cell Minimum Temperature Validity";
BA_ "GenSigStartValue" SG_ 674 BMSCellMinTem_h6HSC6 255;
BA_ "GenSigLongName" SG_ 674 BMSCellMinTem_h6HSC6 "Battery Management System Cell Minimum Temperature";
BA_ "GenSigLongName" SG_ 674 BMSChrgReqHSC6 "Battery Management System Charge Request";
BA_ "GenSigStartValue" SG_ 674 BMSOdoFctHSC6 255;
BA_ "GenSigLongName" SG_ 674 BMSOdoFctHSC6 "Battery Management System Odometer Factor";
BA_ "GenSigStartValue" SG_ 674 BMSOdoFctVHSC6 1;
BA_ "GenSigLongName" SG_ 674 BMSOdoFctVHSC6 "Battery Management System Odometer Factor Validity";
BA_ "GenSigLongName" SG_ 674 BMSOfbdChrgrPlugOn_h6HSC6 "Battery Management System Offboard Charger Plug On";
BA_ "GenSigLongName" SG_ 674 BMSOnbdChrgrPlugOn_h6HSC6 "Battery Management System Onboard Charger Plug On";
BA_ "GenSigStartValue" SG_ 674 VehElecRng_h6HSC6 2046;
BA_ "GenSigLongName" SG_ 674 VehElecRng_h6HSC6 "Vehicle Electric Range";
BA_ "GenSigStartValue" SG_ 939 HVBatElecEnrgAvgRate_h6HSC6 1023;
BA_ "GenSigLongName" SG_ 939 HVBatElecEnrgAvgRate_h6HSC6 "High Voltage Battery Electric Energy Average Rate";
BA_ "GenSigStartValue" SG_ 940 BMSPackSOCDsp_h6HSC6 1023;
BA_ "GenSigLongName" SG_ 940 BMSPackSOCDsp_h6HSC6 "Battery Management System Pack State Of Charge Display";
BA_ "GenSigStartValue" SG_ 913 BMSChrgngRmnngStTime_h6HSC6 2046;
BA_ "GenSigLongName" SG_ 913 BMSChrgSts_h6HSC6 "Battery Management System Charge Status";
BA_ "GenSigStartValue" SG_ 913 BMSReserDurtnTimeDspCmd_h6HSC6 62;
BA_ "GenSigLongName" SG_ 913 BMSReserDurtnTimeDspCmd_h6HSC6 "Battery Management System Reservation Duration Time Display Command";
BA_ "GenSigLongName" SG_ 913 BMSReserPushItemHSC6 "Battery Management System Reservation Push Items";
BA_ "GenSigStartValue" SG_ 913 BMSReserStDurtnTimeDspCmdHSC6 30;
BA_ "GenSigLongName" SG_ 913 BMSReserStDurtnTimeDspCmdHSC6 "Battery Management System Reservation Start Duration Time Display Command";
BA_ "GenSigStartValue" SG_ 913 BMSReserStHourDspCmd_h6HSC6 30;
BA_ "GenSigLongName" SG_ 913 BMSReserStHourDspCmd_h6HSC6 "Battery Management System Reservation Start Hour Display Command";
BA_ "GenSigStartValue" SG_ 913 BMSReserStMinuteDspCmdHSC6 62;
BA_ "GenSigLongName" SG_ 913 BMSReserStMinuteDspCmdHSC6 "Battery Management System Reservation Start Minute Display Command";
BA_ "GenSigLongName" SG_ 915 BMSReserChrgCtrlDspCmdHSC6 "Battery Management System Reservation Charge Control Display Command";
BA_ "GenSigStartValue" SG_ 915 BMSReserChrgEnrgDspCmd_h6HSC6 63;
BA_ "GenSigLongName" SG_ 915 BMSReserChrgEnrgDspCmd_h6HSC6 "Battery Management System Reservation Charge Energy Display Command";
BA_ "GenSigLongName" SG_ 915 BMSReserChrgFltReasonHSC6 "Battery Management System Reservation Charge Fault Reason";
BA_ "GenSigLongName" SG_ 915 BMSReserChrgFrqcDspCmdHSC6 "Battery Management System Reservation Charge Frequency Display Command";
BA_ "GenSigLongName" SG_ 915 BMSReserChrgMdDspCmd_h6HSC6 "Battery Management System Reservation Charge Mode Display Command";
BA_ "GenSigLongName" SG_ 915 BMSReserChrgRespVHSC6 "Battery Management System Reservation Charge Response Validity";
BA_ "GenSigStartValue" SG_ 915 BMSReserChrgRngDspCmd_h6HSC6 1022;
BA_ "GenSigLongName" SG_ 915 BMSReserChrgRngDspCmd_h6HSC6 "Battery Management System Reservation Charge Range Display Command";
BA_ "GenSigLongName" SG_ 915 BMSReserFltReasonHSC6 "Battery Management System Reservation Fault Reason";
BA_ "GenSigStartValue" SG_ 915 BMSReserMaxCrntDspCmd_h6HSC6 63;
BA_ "GenSigLongName" SG_ 915 BMSReserMaxCrntDspCmd_h6HSC6 "Battery Management System Reservation Maximun Current Display Command";
BA_ "GenSigLongName" SG_ 915 BMSReserStaDspCmdHSC6 "Battery Management System Reservation State Display Command";
BA_ "GenSigStartValue" SG_ 915 BMSReserTrgtSOCDspCmd_h6HSC6 1022;
BA_ "GenSigStartValue" SG_ 936 ChrgngRmnngTimeV_h6HSC6 1;
BA_ "GenSigLongName" SG_ 936 ChrgngRmnngTimeV_h6HSC6 "Charging Remaining Time Validity";
BA_ "GenSigStartValue" SG_ 936 ChrgngRmnngTime_h6HSC6 1023;
BA_ "GenSigLongName" SG_ 936 ChrgngRmnngTime_h6HSC6 "Charging Remaining Time";
BA_ "GenSigLongName" SG_ 1091 wake_network_BMSHSC6 "Wake Network Battery Management System";
BA_ "GenSigLongName" SG_ 916 EPTChrgCoolngSysStsHSC6 "Electric Powertrain Charge Cooling system Status";
BA_ "GenSigStartValue" SG_ 916 OfbdChrgrNgtvSktTemHSC6 254;
BA_ "GenSigLongName" SG_ 916 OfbdChrgrNgtvSktTemHSC6 "Offboard Charger Negative Socket Temperature";
BA_ "GenSigStartValue" SG_ 916 OfbdChrgrNgtvSktTemVHSC6 1;
BA_ "GenSigLongName" SG_ 916 OfbdChrgrNgtvSktTemVHSC6 "Offboard Charger Negative Socket Temperature Validity";
BA_ "GenSigStartValue" SG_ 916 OfbdChrgrPstvSktTemHSC6 254;
BA_ "GenSigLongName" SG_ 916 OfbdChrgrPstvSktTemHSC6 "Offboard Charger Positive Socket Temperature";
BA_ "GenSigStartValue" SG_ 916 OfbdChrgrPstvSktTemVHSC6 1;
BA_ "GenSigLongName" SG_ 916 OfbdChrgrPstvSktTemVHSC6 "Offboard Charger Positive Socket Temperature Validity";
BA_ "GenSigLongName" SG_ 916 OnbdChrgrSktEleccLckSHSC6 "Onboard Charger Socket Electronic Lock Status";
BA_ "GenSigLongName" SG_ 138 EPTHVBatPwrRlseReqHSC6 "Electric Powertrain High Voltage Battery Power Release Request";
BA_ "GenSigLongName" SG_ 138 EPTHVEmgcPwrOffReqHSC6 "Electric Powertrain High Voltage Emergency Power Off Request";
BA_ "GenSigLongName" SG_ 138 EPTMainRelayDrvReqHSC6 "Electric Powertrain Main Relay Drive Request";
BA_ "GenSigLongName" SG_ 138 HCUChecksum05HSC6 "Hybrid Countrol Unit Checksum Frp05";
BA_ "GenSigLongName" SG_ 138 HCUCounter05HSC6 "Hybrid Countrol Unit Counter Frp05";
BA_ "GenSigStartValue" SG_ 150 ISGInvtrCrntHSC6 1024;
BA_ "GenSigLongName" SG_ 150 ISGInvtrCrntHSC6 "Integrated Starter Generator Inverter Current";
BA_ "GenSigStartValue" SG_ 150 ISGInvtrCrntVHSC6 1;
BA_ "GenSigLongName" SG_ 150 ISGInvtrCrntVHSC6 "Integrated Starter Generator Inverter Current Validity";
BA_ "GenSigLongName" SG_ 917 ISGInvtrVolHSC6 "Integrated Starter Generator Inverter Voltage";
BA_ "GenSigLongName" SG_ 917 ISGInvtrVolVHSC6 "Integrated Starter Generator Inverter Voltage Validity";
BA_ "GenSigStartValue" SG_ 1053 TBOXUnvslTimeChksmHSC6 254;
BA_ "GenSigLongName" SG_ 1053 TBOXUnvslTimeChksmHSC6 "Telematics Box Universal Time Checksum";
BA_ "GenSigStartValue" SG_ 854 TBOXReserDurtnTimeHSC6 62;
BA_ "GenSigLongName" SG_ 854 TBOXReserDurtnTimeHSC6 "Telematics Box Reservation Duration Time";
BA_ "GenSigStartValue" SG_ 854 TBOXReserStDayHSC6 30;
BA_ "GenSigLongName" SG_ 854 TBOXReserStDayHSC6 "Telematics Box Reservation Charge Start Day";
BA_ "GenSigStartValue" SG_ 854 TBOXReserStDurtnTimeHSC6 30;
BA_ "GenSigLongName" SG_ 854 TBOXReserStDurtnTimeHSC6 "Telematics Box Reservation Start Duration Time";
BA_ "GenSigStartValue" SG_ 854 TBOXReserStHourHSC6 30;
BA_ "GenSigLongName" SG_ 854 TBOXReserStHourHSC6 "Telematics Box Reservation Start Hour";
BA_ "GenSigStartValue" SG_ 854 TBOXReserStMinuteHSC6 62;
BA_ "GenSigLongName" SG_ 854 TBOXReserStMinuteHSC6 "Telematics Box Reservation Start Minute";
BA_ "GenSigLongName" SG_ 854 TBOXReserStMonthHSC6 "Telematics Box Reservation Start Month";
BA_ "GenSigStartValue" SG_ 854 TBOXReserStTimeChksmHSC6 254;
BA_ "GenSigLongName" SG_ 854 TBOXReserStTimeChksmHSC6 "Telematics Box Reservation Start Time Checksum";
BA_ "GenSigStartValue" SG_ 854 TBOXReserStYearHSC6 254;
BA_ "GenSigLongName" SG_ 854 TBOXReserStYearHSC6 "Telematics Box Reservation Start Year";
BA_ "GenSigLongName" SG_ 856 TBOXReserChrgCtrlReqHSC6 "Telematics Box Reservation Charge Control Request";
BA_ "GenSigStartValue" SG_ 856 TBOXReserChrgEnrgHSC6 62;
BA_ "GenSigLongName" SG_ 856 TBOXReserChrgEnrgHSC6 "Telematics Box Reservation Charge Energy";
BA_ "GenSigLongName" SG_ 856 TBOXReserChrgFrqcHSC6 "Telematics Box Reservation Charge Frequency";
BA_ "GenSigLongName" SG_ 856 TBOXReserChrgMdReqHSC6 "Telematics Box Reservation Charge Mode Request";
BA_ "GenSigStartValue" SG_ 856 TBOXReserChrgRngHSC6 1022;
BA_ "GenSigLongName" SG_ 856 TBOXReserChrgRngHSC6 "Telematics Box Reservation Charge Range";
BA_ "GenSigStartValue" SG_ 856 TBOXReserMaxCrntHSC6 62;
BA_ "GenSigLongName" SG_ 856 TBOXReserMaxCrntHSC6 "Tbox Reservation Maximun Current";
BA_ "GenSigStartValue" SG_ 856 TBOXReserTrgtSOCHSC6 1022;
BA_ "GenSigLongName" SG_ 856 TBOXReserTrgtSOCHSC6 "Telematics Box Reservation Target Soc";
BA_ "GenSigStartValue" SG_ 1055 signal_config_id_h6 24833;
BA_ "GenSigStartValue" SG_ 153 TMInvtrCrntHSC6 1024;
BA_ "GenSigLongName" SG_ 153 TMInvtrCrntHSC6 "Traction Motor Inverter Current";
BA_ "GenSigStartValue" SG_ 153 TMInvtrCrntVHSC6 1;
BA_ "GenSigLongName" SG_ 153 TMInvtrCrntVHSC6 "Traction Motor Inverter Current Validity";
BA_ "GenSigLongName" SG_ 331 TMInvtrVolHSC6 "Traction Motor Inverter Voltage";
BA_ "GenSigLongName" SG_ 331 TMInvtrVolVHSC6 "Traction Motor Inverter Voltage Volidity";
BA_ "GenSigStartValue" SG_ 818 CoxtyOfstPosOnXAxisHSC6 254;
BA_ "GenSigStartValue" SG_ 818 CoxtyOfstPosOnYAxisHSC6 254;
BA_ "GenSigStartValue" SG_ 818 FornObjPosDetOnXAxisHSC6 63;
BA_ "GenSigStartValue" SG_ 818 FornObjPosDetOnYAxisHSC6 63;
VAL_ 952 ChargerACCurrentHSC6 255 "fail" ;
VAL_ 952 ChargerACVoltHSC6 255 "fail" ;
VAL_ 952 ChargerFanStatusHSC6 2 "failure" 1 "closed" 0 "open" ;
VAL_ 952 ChargerHVCurrentHSC6 1023 "fail" ;
VAL_ 952 ChargerHVRelayStatusHSC6 2 "failure" 1 "closed" 0 "open" ;
VAL_ 952 ChargerHVVoltHSC6 32767 "fail" ;
VAL_ 952 ChargerStatusHSC6 10 "Stop" 9 "Fault" 7 "Warning" 5 "Charging" 3 "Ready" 1 "Powerup" 0 "idle" ;
VAL_ 952 ChargerWakeUpHSC6 1 "TRUE" 0 "FALSE" ;
VAL_ 952 OnbdChrgCPPwmDutyHSC6 127 "Error" 0 "% (0x0 - 0x7E)" ;
VAL_ 952 OnbdChrgCPPwmStatHSC6 7 "CP out of range" 6 "CP 12V PWM" 5 "CP 12V" 4 "CP 6V PWM" 3 "CP 6V" 2 "CP 9V PWM" 1 "CP 0V" 0 "CP 9V" ;
VAL_ 956 ChargerInsideTemp3HSC6 255 "fail" ;
VAL_ 956 ChargerLVCurrentHSC6 255 "fail" ;
VAL_ 956 ChargerLVVoltHSC6 255 "fail" ;
VAL_ 956 ChrgrAltCrntLmtHSC6 255 "Fail" ;
VAL_ 956 OnChrgCmdHSC6 3 "Restart" 2 "Shut Down" 1 "Enable Charging" 0 "Default" ;
VAL_ 956 OnChrgngFltHSC6 1 "TRUE" 0 "FALSE" ;
VAL_ 956 OnChrgrFltHSC6 1 "TRUE" 0 "FALSE" ;
VAL_ 958 BMSCellTemVHSC6 1 "Invalid" 0 "Valid" ;
VAL_ 958 BMSCellVolVHSC6 1 "Invalid" 0 "Valid" ;
VAL_ 659 BMSBalancingDoneHSC6 1 "TRUE" 0 "FALSE" ;
VAL_ 659 BMSBalancingStatusHSC6 1 "TRUE" 0 "FALSE" ;
VAL_ 659 BMSCellBalancingCountHSC6 255 "Error" 254 "Init" ;
VAL_ 659 BMSCellOverVoltHSC6 1 "TRUE" 0 "FALSE" ;
VAL_ 659 BMSCellUnderVoltHSC6 1 "TRUE" 0 "FALSE" ;
VAL_ 659 BMSContactorPowerCmdHSC6 1 "on" 0 "off" ;
VAL_ 659 BMSContactorPowerMonHSC6 1 "on" 0 "off" ;
VAL_ 659 BMSCrashCircuitStatusHSC6 1 "Open" 0 "Closed" ;
VAL_ 659 BMSEEpromWipHSC6 1 "TRUE" 0 "FALSE" ;
VAL_ 659 BMSLVBatInputHSC6 255 "Error" 254 "Init" ;
VAL_ 659 BMSModuleEnableHSC6 1 "TRUE" 0 "FALSE" ;
VAL_ 659 BMSNegRelayStatusHSC6 2 "failure" 1 "closed" 0 "open" ;
VAL_ 659 BMSOffbdChargerWakeupHSC6 1 "active" 0 "not active" ;
VAL_ 659 BMSOnbdChargerWakeupHSC6 1 "active" 0 "not active" ;
VAL_ 659 BMSPosRelayStatusHSC6 2 "failure" 1 "closed" 0 "open" ;
VAL_ 659 BMSPreRelayStatusHSC6 2 "failure" 1 "closed" 0 "open" ;
VAL_ 659 BMSPTIsolationLevelHSC6 3 "Isolation EPO" 2 "Isolation Alarm" 1 "Isolation Warning" 0 "Isolation OK" ;
VAL_ 659 BMSReadyHSC6 1 "TRUE" 0 "FALSE" ;
VAL_ 659 BMSRelayStepHSC6 12 "main PN closed" 11 "main PN closed DRIVE" 10 "failed mainP open  " 9 "open mainR" 8 "close mainP " 7 "wait precharge" 6 "failed mainN open" 5 "close mainN" 4 "failed mainN weld" 3 "failed mainR open" 2 "close mainR" 1 "failed mainP or R welded" 0 "all open" ;
VAL_ 659 BMSVehicleWakeupHSC6 1 "active" 0 "not active" ;
VAL_ 661 BMSPackCrntV_h6HSC6 1 "Invalid" 0 "Valid" ;
VAL_ 661 BMSPackSOCVHSC6 1 "Invalid" 0 "Valid" ;
VAL_ 661 BMSPackVolV_h6HSC6 1 "Invalid" 0 "Valid" ;
VAL_ 663 BMSBscSta_h6HSC6 20 "Wireless Pre-charging" 19 "Wireless Charging Done" 18 "Wireless Charging Mode" 17 "Wireless Charge Ready" 16 "Off-board Pre-charging" 15 "Fault" 14 "Balancing" 13 "Collision Mode" 12 "On-board Pre-charging" 10 "On-board Charging Done" 9 "Off-board Charging Done" 8 "Offline Balance" 7 "Off-board Charging Mode" 6 "On-board Charging Mode" 5 "Off-board Charge Ready" 4 "On-board Charge Ready" 3 "Drive Mode" 2 "Drive Pre-charging" 1 "Drive Ready" 0 "Power Up" ;
VAL_ 663 BMSFltLvlHSC6 5 "Hard EPO" 4 "Soft EPO" 3 "Alarm 2" 2 "Alarm 1" 1 "Warning" 0 "None" ;
VAL_ 663 BMSHVILClsdHSC6 1 "True" 0 "False" ;
VAL_ 663 BMSMainRelaySts_h6HSC6 3 "Failure" 2 "Partly Closed" 1 "All Closed" 0 "All Open" ;
VAL_ 663 BMSOfbdChrgRelayStsHSC6 2 "Failure" 1 "closed" 0 "open" ;
VAL_ 663 BMSOnbdChrgRelayStsHSC6 2 "Failure" 1 "closed" 0 "open" ;
VAL_ 663 BMSPtIsltnRstcVHSC6 1 "Invalid" 0 "Valid" ;
VAL_ 663 BMSVehEmgcPwrOffHSC6 14 "Init" 8 "OCWhileCharge" 7 "OCWhileDischarge" 6 "HVBusError" 5 "CloseCmdError" 4 "OCWhilePowerDown" 3 "CrashCircuitOpen" 2 "VehCANMissing" 1 "LVBatterylow" ;
VAL_ 663 OffbdChrgrSysKeepAwkHSC6 1 "True" 0 "False" ;
VAL_ 663 OnbdChrgrSktEleccLckEHSC6 2 "Unlock Request" 1 "Lock Request" 0 "Default" ;
VAL_ 663 OnbdChrgrSysKeepAwkHSC6 1 "True" 0 "False" ;
VAL_ 369 BMSChrgCrntLmtVHSC6 1 "Invalid" 0 "Valid" ;
VAL_ 369 BMSDschrgCrntLmtVHSC6 1 "Invalid" 0 "Valid" ;
VAL_ 369 BMSMaxVolLmtVHSC6 1 "Invalid" 0 "Valid" ;
VAL_ 369 BMSMinVolLmtVHSC6 1 "Invalid" 0 "Valid" ;
VAL_ 668 ChargeCurrentHSC6 1023 "fail" ;
VAL_ 668 ChargePowerHSC6 255 "fail" ;
VAL_ 668 ChargerCapacityHSC6 255 "fail" ;
VAL_ 668 ChargerInletTempHSC6 255 "fail" ;
VAL_ 668 ChargerModeHSC6 3 "power control mode" 2 "voltage control mode" 1 "current control mode" 0 "Invalid" ;
VAL_ 665 BMSNegativeBusVoltHSC6 4095 "Error" 4094 "Init" ;
VAL_ 665 BMSPackCurrent2HSC6 65535 "Error" 65534 "Init" ;
VAL_ 665 BMSPackSOCActualHSC6 255 "Error" 254 "Init" ;
VAL_ 665 BMSPositiveBusVoltHSC6 4095 "Error" 4094 "Init" ;
VAL_ 667 BMSBusbarTempMaxHSC6 255 "Error" 254 "Init" ;
VAL_ 667 BMSChgIndDriverStatHSC6 1 "Open" 0 "Closed" ;
VAL_ 667 BMSChrgrPlugCnctnIO_h6HSC6 1 "Lamp Off" 0 "Lamp On" ;
VAL_ 667 BMSChrgStsIO_h6HSC6 1 "Lamp Off" 0 "Lamp On" ;
VAL_ 667 BMSConIndDriverStatHSC6 1 "Open" 0 "Closed" ;
VAL_ 667 BMSLiquidSensorStHSC6 3 "OOR High" 2 "OOR Low" 1 "Fault" 0 "OK" ;
VAL_ 667 BMSPackSOHHSC6 1023 "Error" 1022 "Init" ;
VAL_ 667 BMSStaOfHealthCapctHSC6 255 "Error" 254 "Init" ;
VAL_ 667 BMSStaOfHealthResiHSC6 255 "Error" 254 "Init" ;
VAL_ 1100 keep_network_BMSHSC6 1 "keep network request" 0 "no keep network request" ;
VAL_ 370 BMSChrgPeakPwrVHSC6 1 "Invalid" 0 "Valid" ;
VAL_ 370 BMSChrgPwrLmtVHSC6 1 "Invalid" 0 "Valid" ;
VAL_ 370 BMSDschrgPeakPwrVHSC6 1 "Invalid" 0 "Valid" ;
VAL_ 370 BMSDschrgPwrLmtVHSC6 1 "Invalid" 0 "Valid" ;
VAL_ 371 BMSCellMaxVolVHSC6 1 "Invalid" 0 "Valid" ;
VAL_ 371 BMSCellMinVolVHSC6 1 "Invalid" 0 "Valid" ;
VAL_ 371 BMSChrgBufVHSC6 1 "Invalid" 0 "Valid" ;
VAL_ 371 BMSDschrgBufVHSC6 1 "Invalid" 0 "Valid" ;
VAL_ 674 BMSCellMaxTemV_h6HSC6 1 "Invalid" 0 "Valid" ;
VAL_ 674 BMSCellMinTemV_h6HSC6 1 "Invalid" 0 "Valid" ;
VAL_ 674 BMSChrgReqHSC6 3 "Reserved" 2 "Charge Fault" 1 "Charge Request" 0 "No Charge Request" ;
VAL_ 674 BMSOdoFctVHSC6 1 "Invalid" 0 "Valid" ;
VAL_ 674 BMSOfbdChrgrPlugOn_h6HSC6 1 "True" 0 "False" ;
VAL_ 674 BMSOnbdChrgrPlugOn_h6HSC6 1 "True" 0 "False" ;
VAL_ 940 BMSPackSOCDspV_h6HSC6 1 "Invalid" 0 "Valid" ;
VAL_ 913 BMSChrgSts_h6HSC6 5 "Reserved" 4 "Charge Fault" 3 "Balancing" 2 "Charge Done" 1 "Charging" 0 "None" ;
VAL_ 913 BMSReserPushItemHSC6 8 "Electric Lock Abnormal" 7 "Reserve information updated to the next day" 6 "Reserve Information Update Failure" 5 "Charging Complete" 4 "Charging Start" 3 "Charge Cease" 2 "Charging Fault" 1 "Charging Gun Not Plug In" 0 "None" ;
VAL_ 915 BMSReserChrgCtrlDspCmdHSC6 4 "Reserved" 3 "Command Execute Failed" 2 "Command Execute Success" 1 "Command Accept" 0 "None" ;
VAL_ 915 BMSReserChrgFltReasonHSC6 4096 "Reserved" 2048 "Voltage Mismatch" 1024 "Current Mismatch" 512 "Voltage Low" 256 "Voltage High" 128 "Current Low" 64 "Current High" 32 "Temperature Low" 16 "Temperature High" 8 "Communication Fault" 4 "Isolation Fault" 2 "HVIL Satus Abnormal" 1 "Charger Not Ready" 0 "None" ;
VAL_ 915 BMSReserChrgFrqcDspCmdHSC6 3 "Reserved" 2 "Daily" 1 "Once" 0 "None" ;
VAL_ 915 BMSReserChrgMdDspCmd_h6HSC6 4 "Soc Based Mode" 3 "Range Based Mode" 2 "Energy Based Mode" 1 "Time Based Mode" 0 "Unavailable" ;
VAL_ 915 BMSReserChrgRespVHSC6 1 "invalid" 0 "valid" ;
VAL_ 915 BMSReserFltReasonHSC6 5 "Global Time Set Failure" 4 "Global Time Not Reasonable" 3 "Time Setting Not Reasonable" 2 "BMS Set RTC Failed" 1 "EEPROM Storage Failed" 0 "None" ;
VAL_ 915 BMSReserStaDspCmdHSC6 3 "Reserved" 2 "Reservation Switch Off" 1 "Reservation Switch On" 0 "None" ;
VAL_ 936 BMSWrlsChrgnFltReason_h6HSC6 19 "wireless charging fault" 18 "Door not locked" 17 "WLC system fault" 9 "WLC primary side fault" 8 "WLC wall side fault" 4 "WLC ground side fault" 2 "WLC vehicle side fault" 1 "WLC system ready" 0 "init" ;
VAL_ 936 BMSWrlsChrgngResp_h6HSC6 4 "wireless charging switch off" 2 "wireless charging switch on by TBox" 1 "wireless charging switch on by FICM" 0 "None" ;
VAL_ 936 ChrgngRmnngTimeV_h6HSC6 1 "Invalid" 0 "Valid" ;
VAL_ 820 BMSWkupWrlsChrgrHSC6 1 "wakeup" 0 "not wakeup" ;
VAL_ 820 BMSWrlsChrgngCmdHSC6 3 "Restart" 2 "Shut down" 1 "Enable Charging" 0 "default" ;
VAL_ 820 BMSWrlsChrgngFltHSC6 1 "fault" 0 "no fault" ;
VAL_ 820 BMSWrlsChrgngMdHSC6 3 "current control mode" 2 "voltage control mode" 1 "power control mode" 0 "Invalid" ;
VAL_ 820 BMSWrlsChrgngSftyHSC6 1 "not safe" 0 "safe" ;
VAL_ 820 BMSWrlsChrgrFltHSC6 1 "fault" 0 "no fault" ;
VAL_ 1091 wake_network_BMSHSC6 1 "wake-up network request" 0 "no wake-up network request" ;
VAL_ 916 EPTChrgCoolngSysStsHSC6 7 "Reserved" 6 "Reserved" 5 "Reserved" 4 "Reserved" 3 "Reserved" 2 "Cooling system Unable" 1 "Cooling system Limited" 0 "Cooling system Normal" ;
VAL_ 916 OfbdChrgrNgtvSktTemVHSC6 1 "Invalid" 0 "Valid" ;
VAL_ 916 OfbdChrgrPstvSktTemVHSC6 1 "Invalid" 0 "Valid" ;
VAL_ 916 OnbdChrgrSktEleccLckSHSC6 3 "Electronic Lock Feedback Error" 2 "Electronic Lock Control Line Failure" 1 "Locked" 0 "Unlocked" ;
VAL_ 138 EPTHVBatPwrRlseReqHSC6 1 "request" 0 "no request" ;
VAL_ 138 EPTHVEmgcPwrOffReqHSC6 1 "request" 0 "no request" ;
VAL_ 138 EPTMainRelayDrvReqHSC6 3 "Reserved" 2 "Close Fast Charge Relay" 1 "Close Main Relay" 0 "Open Request" ;
VAL_ 150 ISGInvtrCrntVHSC6 1 "Invalid" 0 "Valid" ;
VAL_ 917 ISGInvtrVolVHSC6 1 "Invalid" 0 "Valid" ;
VAL_ 1053 TBOXUnvslTimeCalendarMHSC6 12 "December" 11 "November" 10 "October" 9 "September" 8 "August" 7 "July" 6 "June" 5 "May" 4 "April" 3 "March" 2 "February" 1 "January" 0 "Unknown" ;
VAL_ 854 TBOXReserStMonthHSC6 12 "December" 11 "November" 10 "October" 9 "September" 8 "August" 7 "July" 6 "June" 5 "May" 4 "April" 3 "March" 2 "February" 1 "January" 0 "Unknown" ;
VAL_ 856 TBOXReserChrgCtrlReqHSC6 5 "Reserved" 4 "Stop Charge" 3 "Start Charge" 2 "Reservation Switch Off" 1 "Reservation Switch On" 0 "None" ;
VAL_ 856 TBOXReserChrgFrqcHSC6 3 "Reserved" 2 "Daily" 1 "Once" 0 "None" ;
VAL_ 856 TBOXReserChrgMdReqHSC6 4 "Soc Based Mode" 3 "Range Based Mode" 2 "Energy Based Mode" 1 "Time Based Mode" 0 "None" ;
VAL_ 856 TBOXWrlsChrgngReqHSC6 3 "Reserved" 2 "Wireless charging switch off" 1 "Wireless charging switch on" 0 "No Request" ;
VAL_ 1055 network_mode_h6 2 "normal" 1 "shutdown" 0 "start-up" ;
VAL_ 1055 signal_config_id_h6 17457 "config: IP34 EP/PPV" ;
VAL_ 153 TMInvtrCrntVHSC6 1 "Invalid" 0 "Valid" ;
VAL_ 331 TMInvtrVolVHSC6 1 "Invalid" 0 "Valid" ;
VAL_ 818 CoxtyBtwnPriyAndSecyCoilFltHSC6 2 "fault" 1 "no fault" 0 "init" ;
VAL_ 818 FornObjDetHSC6 2 "fault" 1 "no fault" 0 "init" ;
VAL_ 826 WrlsChrgrGndSideStsHSC6 5 "Powerup" 4 "fault" 3 "stop" 2 "working" 1 "standby" 0 "idle" ;
VAL_ 826 WrlsChrgrStsHSC6 12 "Poweroff" 10 "Stop" 9 "Fault" 7 "Warning" 5 "Charging" 3 "Ready" 1 "Powerup" 0 "idle" ;
VAL_ 826 WrlsChrgrVehSideStsHSC6 5 "Powerup" 4 "fault" 3 "stop" 2 "working" 1 "standby" 0 "idle" ;
VAL_ 826 WrlsChrgrWallSideStsHSC6 5 "Powerup" 4 "fault" 3 "stop" 2 "working" 1 "standby" 0 "idle" ;
VAL_ 826 WrlsChrgrWkupAHSC6 1 "True" 0 "False" ;
